CM_ "IMPORT _hyundai_canfd_common.dbc";

BO_ 53 ACCELERATOR: 32 XXX
 SG_ CHECKSUM : 0|16@1+ (1,0) [0|65535] "" XXX
 SG_ COUNTER : 16|8@1+ (1,0) [0|255] "" XXX
 SG_ ACCELERATOR_PEDAL : 40|8@1+ (1,0) [0|255] "" XXX
 SG_ GEAR : 192|3@1+ (1,0) [0|7] "" XXX

BO_ 64 GEAR_ALT: 32 XXX
 SG_ CHECKSUM : 0|16@1+ (1,0) [0|65535] "" XXX
 SG_ COUNTER : 16|8@1+ (1,0) [0|255] "" XXX
 SG_ GEAR : 32|3@1+ (1,0) [0|7] "" XXX
 SG_ GEAR_STEP : 67|4@0+ (1,0) [0|15] "" XXX
 SG_ NEW_SIGNAL_4 : 68|4@1+ (1,0) [0|15] "" XXX
 SG_ NEW_SIGNAL_1 : 75|4@0+ (1,0) [0|15] "" XXX
 SG_ NEW_SIGNAL_3 : 76|4@1+ (1,0) [0|15] "" XXX

BO_ 69 GEAR: 24 XXX
 SG_ CHECKSUM : 0|16@1+ (1,0) [0|65535] "" XXX
 SG_ COUNTER : 16|8@1+ (1,0) [0|255] "" XXX
 SG_ GEAR : 44|3@1+ (1,0) [0|7] "" XXX
 SG_ RIGHT_PADDLE : 57|1@0+ (1,0) [0|1] "" XXX
 SG_ LEFT_PADDLE : 58|1@0+ (1,0) [0|1] "" XXX
 SG_ GEAR_STEP : 146|5@1+ (1,0) [0|31] "" XXX
 SG_ GEAR_STEP1 : 154|5@1+ (1,0) [0|31] "" XXX

BO_ 74 IMU_01_10ms: 32 CGW_CCU
 SG_ IMU_Crc1Val : 0|16@1+ (1,0) [0|0] ""  ECS,ESC,FCU_C,GW_RGW,ICSC,MDPS,RCU,RWS,SFA,VPC_C
 SG_ IMU_AlvCnt1Val : 16|8@1+ (1,0) [0|0] ""  ECS,ESC,FCU_C,GW_RGW,ICSC,MDPS,RCU,RWS,SFA,VPC_C
 SG_ IMU_YawSigSta : 24|4@1+ (1,0) [0|15] ""  CLU,ADAS_PRK,FR_CMR,RR_C_RDR
 SG_ IMU_LatAccelSigSta : 28|4@1+ (1,0) [0|15] ""  CLU,ADAS_PRK,FR_CMR,RR_C_RDR
 SG_ IMU_LongAccelSigSta : 32|4@1+ (1,0) [0|15] ""  CLU,ADAS_PRK,FR_CMR,RR_C_RDR
 SG_ IMU_VerAccelSigSta : 36|4@1+ (1,0) [0|15] "" XXX
 SG_ IMU_McuVoltSta : 40|4@1+ (1,0) [0|15] "" XXX
 SG_ IMU_AcuRstSta : 44|4@1+ (1,0) [0|15] "" XXX
 SG_ IMU_SnsrTyp : 48|8@1+ (1,0) [0|255] "" XXX
 SG_ IMU_RollSigSta : 56|8@1+ (1,0) [0|255] "" XXX
 SG_ IMU_YawRtVal : 64|16@1+ (0.005,-163.84) [-163.84|163.835] "Deg/s"  CLU,ADAS_PRK,FR_CMR,RR_C_RDR
 SG_ IMU_LatAccelVal : 80|16@1+ (0.000127465,-4.17677312) [-4.17677312|4.176645655] "g"  CLU,ADAS_PRK,FR_CMR,RR_C_RDR
 SG_ IMU_LongAccelVal : 96|16@1+ (0.000127465,-4.17677312) [-4.17677312|4.176645655] "g"  CLU,ADAS_PRK,FR_CMR,RR_C_RDR
 SG_ IMU_SnsrTempVal : 112|16@1+ (1,0) [0|65535] "" XXX
 SG_ IMU_SeralNumVal : 128|64@1+ (1,0) [0|1.84467440737096e+19] "" XXX
 SG_ IMU_RollRtVal : 192|16@1+ (0.005,-163.84) [0|0] "º/s" XXX
 SG_ IMU_VerAccelVal : 208|8@1+ (1,0) [0|255] "" XXX

BO_ 96 ESP_STATUS: 32 XXX
 SG_ CHECKSUM : 0|16@1+ (1,0) [0|65535] "" XXX
 SG_ COUNTER : 16|8@1+ (1,0) [0|255] "" XXX
 SG_ TRACTION_AND_STABILITY_CONTROL : 42|3@1+ (1,0) [0|63] "" XXX
 SG_ BRAKE_PRESSURE : 128|11@1+ (1,0) [0|2047] "" XXX
 SG_ BRAKE_PRESSED : 148|1@1+ (1,0) [0|3] "" XXX
 SG_ AUTO_HOLD : 192|2@1+ (1,0) [0|3] "" XXX
 SG_ AVH_I_LAMP : 218|2@1+ (1,0) [0|3] "" XXX
 SG_ AVH_LAMP : 220|3@1+ (1,0) [0|7] "" XXX

BO_ 101 BRAKE: 32 XXX
 SG_ CHECKSUM : 0|16@1+ (1,0) [0|65535] "" XXX
 SG_ COUNTER : 16|8@1+ (1,0) [0|255] "" XXX
 SG_ BRAKE_LIGHT : 29|1@0+ (1,0) [0|1] "" XXX
 SG_ BRAKE_POSITION : 40|16@1- (1,0) [0|65535] "" XXX
 SG_ BRAKE_PRESSED : 57|1@1+ (1,0) [0|3] "" XXX

BO_ 112 GEAR_ALT_2: 32 XXX
 SG_ CHECKSUM : 0|16@1+ (1,0) [0|65535] "" XXX
 SG_ COUNTER : 16|8@1+ (1,0) [0|255] "" XXX
 SG_ GEAR : 60|3@1+ (1,0) [0|7] "" XXX

BO_ 147 CANFD_NAVI_PROFILE_093: 24 XXX
 SG_ PROLONG_VALUE : 64|32@1+ (1,0) [0|4294967295] "" XXX
 SG_ PROLONG_OFFSET : 96|13@1+ (1,0) [0|8191] "m" XXX
 SG_ PROLONG_CYCLIC_COUNTER : 109|2@1+ (1,0) [0|3] "" XXX
 SG_ PROLONG_UPDATE : 111|1@1+ (1,0) [0|1] "" XXX
 SG_ PROLONG_PATH_INDEX : 112|6@1+ (1,0) [0|63] "" XXX
 SG_ PROLONG_PROFILE_TYPE : 118|5@1+ (1,0) [0|31] "" XXX

BO_ 160 WHEEL_SPEEDS: 24 XXX
 SG_ CHECKSUM : 0|16@1+ (1,0) [0|65535] "" XXX
 SG_ COUNTER : 16|8@1+ (1,0) [0|255] "" XXX
 SG_ MOVING_FORWARD : 56|1@0+ (1,0) [0|1] "" XXX
 SG_ MOVING_BACKWARD : 57|1@0+ (1,0) [0|1] "" XXX
 SG_ MOVING_FORWARD2 : 58|1@0+ (1,0) [0|1] "" XXX
 SG_ MOVING_BACKWARD2 : 59|1@0+ (1,0) [0|1] "" XXX
 SG_ WHL_SpdFLVal : 64|14@1+ (0.03125,0) [0|0] "km^h" XXX
 SG_ WHL_SpdFRVal : 80|14@1+ (0.03125,0) [0|0] "km^h" XXX
 SG_ WHL_SpdRLVal : 96|14@1+ (0.03125,0) [0|0] "km^h" XXX
 SG_ WHL_SpdRRVal : 112|14@1+ (0.03125,0) [0|0] "km^h" XXX

BO_ 203 LFA_ALT: 24 CGW_CCU
 SG_ CHECKSUM : 0|16@1+ (1,0) [0|65535] "" FCU_C,GW_RGW,MDPS,SFA
 SG_ COUNTER : 16|8@1+ (1,0) [0|255] "" FCU_C,GW_RGW,MDPS,SFA
 SG_ ADAS_AngleActiveStat : 24|4@1+ (1,0) [0|0] "" GW_RGW,MDPS,SFA
 SG_ ADAS_AngleActiveStat_Lv2 : 28|4@1+ (1,0) [0|0] "" ESC,FCU_C,GW_RGW,MDPS,SFA,VPC_C
 SG_ ADAS_AngleReq : 32|14@1- (0.1,0) [0|511] "Deg" GW_RGW,MDPS,SFA
 SG_ ADAS_AngleTorqueGain : 48|8@1+ (1,0) [0|255] "" GW_RGW,MDPS,SFA
 SG_ FCA_ESA_ActiveStat : 56|2@1+ (1,0) [0|0] "" GW_RGW,MDPS,SFA
 SG_ FCA_ESA_ToqueGain : 64|8@1+ (0.004,0) [0|0] "" GW_RGW,MDPS,SFA

BO_ 229 ESC_02_10ms: 32 CGW
 SG_ ESC_YawSigSta : 24|4@1+ (1,0) [0|15] ""  CLU,ADAS_PRK,FR_CMR,RR_C_RDR
 SG_ ESC_LatAccelSigSta : 28|4@1+ (1,0) [0|15] ""  CLU,ADAS_PRK,FR_CMR,RR_C_RDR
 SG_ ESC_LongAccelSigSta : 32|4@1+ (1,0) [0|15] ""  CLU,ADAS_PRK,FR_CMR,RR_C_RDR
 SG_ ESC_YawRtVal : 64|16@1+ (0.005,-163.84) [-163.84|163.835] "Deg/s"  CLU,ADAS_PRK,FR_CMR,RR_C_RDR
 SG_ ESC_LatAccelVal : 80|16@1+ (0.000127465,-4.17677312) [-4.17677312|4.176645655] "g"  CLU,ADAS_PRK,FR_CMR,RR_C_RDR
 SG_ ESC_LongAccelVal : 96|16@1+ (0.000127465,-4.17677312) [-4.17677312|4.176645655] "g"  CLU,ADAS_PRK,FR_CMR,RR_C_RDR

BO_ 234 MDPS: 24 SFA
 SG_ CHECKSUM : 0|16@1+ (1,0) [0|65535] "" CGW_CCU,ESC,ICSC,RCU,RWA,RWS,VPC_C
 SG_ COUNTER : 16|8@1+ (1,0) [0|255] "" CGW_CCU,ESC,ICSC,RCU,RWA,RWS,VPC_C
 SG_ WarningLamp : 24|3@1+ (1,0) [0|0] "" CGW_CCU,ESC,ICSC,RCU,RWA,RWS
 SG_ Type : 27|3@1+ (1,0) [0|0] "" CGW_CCU,ICSC,RWA
 SG_ EngineIdleRpmReq : 30|2@1+ (1,0) [0|0] "" CGW_CCU,RWA
 SG_ VSM_Stat : 32|2@1+ (1,0) [0|0] "flag" ESC,ICSC,RCU,RWA
 SG_ VSM_DefectiveStat : 34|2@1+ (1,0) [0|0] "" ESC,ICSC,RCU,RWA
 SG_ VSM_SignalStat : 36|2@1+ (1,0) [0|0] "" ESC,RCU,RWA
 SG_ PA_Stat : 38|2@1+ (1,0) [0|0] "" CGW_CCU,ESC,RCU,RWA
 SG_ PA_ModeStat : 40|4@1+ (1,0) [0|0] "" CGW_CCU,RWA
 SG_ PA_CanFailStat : 44|2@1+ (1,0) [0|0] "" CGW_CCU,RWA
 SG_ LKA_Stat : 46|2@1+ (1,0) [0|0] "" CGW_CCU,ICSC,RWA
 SG_ LKA_ToiActiveStat : 48|2@1+ (1,0) [0|16777215] "" CGW_CCU,RWA
 SG_ LKA_ToiUnavailStat : 50|2@1+ (1,0) [0|0] "" CGW_CCU,RWA
 SG_ LKA_ToiFaultStat : 52|2@1+ (1,0) [0|0] "" CGW_CCU,RWA
 SG_ LKA_ToiFailStat : 54|2@1+ (1,0) [0|1] "" CGW_CCU,RWA
 SG_ ResetStat : 59|2@1+ (1,0) [0|0] "" Vector__XXX
 SG_ SteerMode : 61|3@1+ (1,0) [0|0] "" CGW_CCU,RWA
 SG_ OutTorque : 64|12@1+ (0.1,-204.8) [0|65535] "Nm" CGW_CCU,ESC,ICSC,RCU,RWA
 SG_ VSM_ActStat : 76|2@1+ (1,0) [0|0] "" ESC,RCU,RWA
 SG_ ReprogramStat : 78|2@1+ (1,0) [0|0] "" CGW_CCU
 SG_ SteerTorqueSensor : 80|13@1+ (1,-4095) [0|4095] "" CGW_CCU,ESC,ICSC,RCU,RWA,VPC_C
 SG_ PA_SteerAngle : 96|16@1- (0.1,0) [0|255] "Deg" CGW_CCU,RWA
 SG_ LoamStat : 112|2@1+ (1,0) [0|0] "" CGW_CCU,RWA
 SG_ HDPSwVer : 114|5@1+ (1,0) [0|0] "" CGW_CCU,RWA
 SG_ ADAS_ActiveStat : 120|4@1+ (1,0) [0|0] "" CGW_CCU,ESC,RWA,RWS
 SG_ ADAS_AciPlugStat : 124|2@1+ (1,0) [0|0] "" RWA
 SG_ ADAS_AciFault : 126|2@1+ (1,0) [0|0] "" CGW_CCU,ESC,RWA
 SG_ EstSteerAngle : 128|16@1- (0.1,0) [0|65535] "Deg" CGW_CCU,RWA,RWS
 SG_ ADAS_ActiveStat_Lv2 : 144|4@1+ (1,0) [0|0] "" CGW_CCU,RWA
 SG_ ADAS_AciFault_Lv2 : 148|3@1+ (1,0) [0|0] "" CGW_CCU,RWA
 SG_ TPA_Stat : 152|2@1+ (1,0) [0|0] "" RWA,VPC_C
 SG_ TPA_CanFailStat : 154|2@1+ (1,0) [0|0] "" RWA,VPC_C
 SG_ TPA_ModeStat : 156|4@1+ (1,0) [0|0] "" RWA,VPC_C
 SG_ TPA_SteerAngle : 160|16@1- (0.1,0) [0|0] "Deg" RWA,VPC_C

BO_ 256 ACCELERATOR_BRAKE_ALT: 32 XXX
 SG_ CHECKSUM : 0|16@1+ (1,0) [0|65535] "" XXX
 SG_ COUNTER : 16|8@1+ (1,0) [0|255] "" XXX
 SG_ BRAKE_PRESSED : 32|1@1+ (1,0) [0|1] "" XXX
 SG_ ACCELERATOR_PEDAL_PRESSED : 176|1@1+ (1,0) [0|1] "" XXX

BO_ 261 ACCELERATOR_ALT: 32 XXX
 SG_ CHECKSUM : 0|16@1+ (1,0) [0|65535] "" XXX
 SG_ COUNTER : 16|8@1+ (1,0) [0|255] "" XXX
 SG_ ACCELERATOR_PEDAL : 103|10@1+ (0.25,0) [0|1022] "" XXX

BO_ 272 LKAS_ALT: 32 XXX
 SG_ CHECKSUM : 0|16@1+ (1,0) [0|65535] "" XXX
 SG_ COUNTER : 16|8@1+ (1,0) [0|255] "" XXX
 SG_ LKA_OptUsmSta : 24|3@1+ (1,0) [0|7] "" ADAS_DRV
 SG_ LKA_RcgSta : 27|3@1+ (1,0) [0|7] "" ADAS_DRV
 SG_ LKA_LHLnWrnSta : 30|2@1+ (1,0) [0|3] "" ADAS_DRV
 SG_ LKA_RHLnWrnSta : 32|2@1+ (1,0) [0|3] "" ADAS_DRV
 SG_ LKA_HndsoffSnd : 34|2@1+ (1,0) [0|3] "" ADAS_DRV
 SG_ LKA_StrSnd : 36|2@1+ (1,0) [0|3] "" ADAS_DRV
 SG_ LKA_ICON : 38|3@1+ (1,0) [0|7] "" ADAS_DRV
 SG_ StrTqReqVal : 41|11@1+ (1,-1024) [0|4095] "" XXX
 SG_ ActToiSta : 52|2@1+ (1,0) [0|3] "" ADAS_DRV
 SG_ ToiFltSta : 54|2@1+ (1,0) [0|3] "" ADAS_DRV
 SG_ LFA_BUTTON : 56|1@1+ (1,0) [0|1] "" XXX
 SG_ LKA_SysWrn : 60|4@1+ (1,0) [0|15] "" ADAS_DRV
 SG_ Damping_Gain : 64|8@1+ (1,0) [0|255] "" CGW
 SG_ ADAS_AngleActiveStat_Lv2 : 77|2@0+ (1,0) [0|3] "" XXX
 SG_ LKA_UsmMod : 80|2@1+ (1,0) [0|3] "" ADAS_DRV
 SG_ ADAS_AngleReq : 82|14@1- (0.1,0) [0|511] "deg" GW_RGW,MDPS,SFA
 SG_ ADAS_AngleTorqueGain : 96|8@1+ (1,0) [0|255] "" GW_RGW,MDPS,SFA
 SG_ FCA_ESA_CtrlSta : 107|1@0+ (1,0) [0|1] "" XXX

BO_ 282 ADAS_CAM: 16 CAMERA
 SG_ CHECKSUM : 0|16@1+ (1,0) [0|65535] "" Dummy,IBU_HS,vBDM
 SG_ COUNTER : 16|8@1+ (1,0) [0|255] "" CLU,IBU_HS,vBDM
 SG_ HBA_SysOptSta : 24|2@1+ (1,0) [0|3] "" CLU,IBU_HS,vBDM
 SG_ HBA_SysSta : 26|3@1+ (1,0) [0|7] "" CLU,IBU_HS,vBDM
 SG_ HBA_IndLmpReq : 29|2@1+ (1,0) [0|3] "" CLU,vBDM
 SG_ iHBAref_VehLeftSta : 31|2@1+ (1,0) [0|3] "" IBU_HS,ICU,vBDM
 SG_ iHBAref_VehCtrSta : 33|2@1+ (1,0) [0|3] "" IBU_HS,ICU,vBDM
 SG_ iHBAref_VehRightSta : 35|2@1+ (1,0) [0|3] "" IBU_HS,ICU,vBDM
 SG_ iHBAref_ILLAmbtSta : 37|2@1+ (1,0) [0|3] "" IBU_HS,ICU,vBDM
 SG_ FCA_Equip_MFC : 39|3@1+ (1,0) [0|0] "" ADAS_DRV,RR_C_RDR,vBDM
 SG_ HBA_OptUsmSta : 42|2@1+ (1,0) [0|3] "" CLU,H_U_MM
 SG_ FCAref_FusSta : 45|3@1+ (1,0) [0|0] "" vBDM
 SG_ DAW_LVDA_PUDis : 48|2@1+ (1,0) [0|0] "" CLU,vBDM
 SG_ DAW_LVDA_OptUsmSta : 50|2@1+ (1,0) [0|3] "" CLU,H_U_MM,vBDM
 SG_ DAW_OptUsmSta : 52|3@1+ (1,0) [0|0] "" CLU,H_U_MM
 SG_ DAW_SysSta : 55|4@1+ (1,0) [0|0] "" CLU
 SG_ DAW_WrnMsgSta : 59|3@1+ (1,0) [0|0] "" CLU
 SG_ DAW_TimeRstReq : 62|2@1+ (1,0) [0|0] "" CLU
 SG_ DAW_SnstvtyModRetVal : 64|3@1+ (1,0) [0|0] "" CLU,H_U_MMz
 SG_ SCCEquipStat : 85|2@1+ (1,0) [0|3] "" CGW
 SG_ DASMapMsg : 96|16@1+ (1,0) [0|65535] "" CGW
 SG_ SwVer1 : 112|4@1+ (1,0) [0|15] "" CGW
 SG_ SwVer2 : 120|8@1+ (1,0) [0|255] "" CGW

BO_ 293 STEERING_SENSORS: 16 XXX
 SG_ CHECKSUM : 0|16@1+ (1,0) [0|65535] "" XXX
 SG_ COUNTER : 16|8@1+ (1,0) [0|255] "" XXX
 SG_ STEERING_ANGLE : 24|16@1- (0.1,0) [0|511] "deg" XXX
 SG_ STEERING_RATE : 40|8@1+ (4,0) [0|1016] "deg/s" XXX

BO_ 298 LFA: 16 ADRV
 SG_ CHECKSUM : 0|16@1+ (1,0) [0|65535] "" CLU,CGW
 SG_ COUNTER : 16|8@1+ (1,0) [0|255] "" CLU,CGW
 SG_ LKA_OptUsmSta : 24|3@1+ (1,0) [0|7] "" CLU,CGW
 SG_ LKA_RcgSta : 27|3@1+ (1,0) [0|7] "" CLU,CGW
 SG_ LKA_LHLnWrnSta : 30|2@1+ (1,0) [0|3] "" CLU,CGW
 SG_ LKA_RHLnWrnSta : 32|2@1+ (1,0) [0|3] "" CLU,CGW
 SG_ LKA_HndsoffSnd : 34|2@1+ (1,0) [0|3] "" CLU,CGW
 SG_ LKA_StrSnd : 36|2@1+ (1,0) [0|3] "" CLU,CGW
 SG_ LKA_ICON : 38|3@1+ (1,0) [0|7] "" CLU,RR_C_RDR,CGW
 SG_ StrTqReqVal : 41|11@1+ (1,-1024) [0|4095] "" XXX
 SG_ ActToiSta : 52|2@1+ (1,0) [0|3] "" CLU,CGW
 SG_ ToiFltSta : 54|2@1+ (1,0) [0|3] "" CGW
 SG_ LFA_BUTTON : 56|1@0+ (1,0) [0|255] "" XXX
 SG_ BCA_Rear_WrnSta : 57|3@1+ (1,0) [0|255] "" ADRV
 SG_ LKA_SysWrn : 60|4@1+ (1,0) [0|15] "" CLU,CGW
 SG_ FCA_LO_WrnSta : 64|1@1+ (1,0) [0|1] "" ADRV
 SG_ FCA_LS_WrnSta : 68|1@1+ (1,0) [0|1] "" ADRV
 SG_ LKA_OnOffEquip2Sta : 72|2@1+ (1,0) [0|255] "" ADRV
 SG_ LKA_UsmMod : 80|2@1+ (1,0) [0|3] "" CLU,CGW
 SG_ Info_PedtrnDst : 84|3@0+ (1,0) [0|7] "" ADAS_DRV
 SG_ ELK_SysFlrSta : 85|5@1+ (1,0) [0|31] "" ADRV
 SG_ ELK_SymbDisp : 90|3@1+ (1,0) [0|7] "" ADRV
 SG_ FCA_ESA_WrnSta : 93|1@1+ (1,0) [0|7] "" ADRV
 SG_ FCA_ESA_CtrlSta : 101|1@1+ (1,0) [0|7] "" ADRV
 SG_ Damping_Gain : 104|8@1+ (1,0) [0|255] "" CGW

BO_ 304 GEAR_SHIFTER: 16 XXX
 SG_ CHECKSUM : 0|16@1+ (1,0) [0|65535] "" XXX
 SG_ COUNTER : 16|8@1+ (1,0) [0|255] "" XXX
 SG_ PARK_BUTTON : 32|2@1+ (1,0) [0|3] "" XXX
 SG_ KNOB_POSITION : 40|3@1+ (1,0) [0|3] "" XXX
 SG_ GEAR : 64|3@1+ (1,0) [0|7] "" XXX

BO_ 352 ADRV_0x160: 16 ADRV
 SG_ CHECKSUM : 0|16@1+ (1,0) [0|65535] "" XXX
 SG_ COUNTER : 16|8@1+ (1,0) [0|255] "" XXX
 SG_ AEB_SETTING : 24|2@1+ (1,0) [0|255] "" XXX
 SG_ NEW_SIGNAL_1 : 30|1@0+ (1,0) [0|1] "" XXX
 SG_ NEW_SIGNAL_4 : 31|1@0+ (1,0) [0|1] "" XXX
 SG_ NEW_SIGNAL_5 : 39|8@0+ (1,0) [0|255] "" XXX
 SG_ NEW_SIGNAL_6 : 47|8@0+ (1,0) [0|255] "" XXX
 SG_ NEW_SIGNAL_2 : 55|8@0+ (1,0) [0|255] "" XXX
 SG_ SET_ME_2 : 56|8@1+ (1,0) [0|1] "" XXX
 SG_ SET_ME_FF : 64|8@1+ (1,0) [0|255] "" XXX
 SG_ SET_ME_FC : 72|8@1+ (1,0) [0|255] "" XXX
 SG_ SET_ME_9 : 80|8@1+ (1,0) [0|255] "" XXX
 SG_ NEW_SIGNAL_3 : 95|8@0+ (1,0) [0|255] "" XXX
 SG_ NEW_SIGNAL_7 : 102|1@0+ (1,0) [0|1] "" XXX

BO_ 353 CCNC_0x161: 32 CCNC
 SG_ CHECKSUM : 0|16@1+ (1,0) [0|65535] "" XXX
 SG_ COUNTER : 16|8@1+ (1,0) [0|255] "" XXX
 SG_ FCA_ICON : 24|3@1+ (1,0) [0|7] "" XXX
 SG_ FCA_ALT_ICON : 27|3@1+ (1,0) [0|7] "" XXX
 SG_ LKA_ICON : 30|3@1+ (1,0) [0|3] "" XXX
 SG_ HBA_ICON : 33|3@1+ (1,0) [0|7] "" XXX
 SG_ FCA_IMAGE : 42|3@1+ (1,0) [0|7] "" XXX
 SG_ BCA_LEFT : 51|3@1+ (1,0) [0|7] "" XXX
 SG_ BCA_RIGHT : 54|3@1+ (1,0) [0|7] "" XXX
 SG_ LCA_LEFT_ARROW : 57|3@1+ (1,0) [0|7] "" XXX
 SG_ LCA_RIGHT_ARROW : 60|3@1+ (1,0) [0|7] "" XXX
 SG_ CENTERLINE : 64|2@1+ (1,0) [0|3] "" XXX
 SG_ TARGET : 66|3@1+ (1,0) [0|7] "" XXX
 SG_ TARGET_DISTANCE : 69|11@1+ (0.1,0) [0|204.7] "m" XXX
 SG_ LANELINE_LEFT : 80|4@1+ (1,0) [0|15] "" XXX
 SG_ LANELINE_LEFT_POSITION : 84|6@1+ (1,0) [0|15] "" XXX
 SG_ LANELINE_RIGHT : 90|4@1+ (1,0) [0|15] "" XXX
 SG_ LANELINE_RIGHT_POSITION : 94|6@1+ (1,0) [0|15] "" XXX
 SG_ LANELINE_CURVATURE : 100|4@1+ (1,0) [0|15] "" XXX
 SG_ LANELINE_CURVATURE_DIRECTION : 104|1@0+ (1,0) [0|1] "" XXX
 SG_ LANE_HIGHLIGHT : 105|4@1+ (1,0) [0|15] "" XXX
 SG_ LANE_HIGHLIGHT_DISTANCE : 109|11@1+ (0.1,0) [0|204.7] "m" XXX
 SG_ LANE_LEFT : 120|3@1+ (1,0) [0|7] "" XXX
 SG_ LANE_RIGHT : 123|3@1+ (1,0) [0|7] "" XXX
 SG_ LANE_ZOOM : 126|2@1+ (1,0) [0|3] "" XXX
 SG_ ALERTS_1 : 128|6@1+ (1,0) [0|63] "" XXX
 SG_ ALERTS_2 : 134|5@1+ (1,0) [0|31] "" XXX
 SG_ ALERTS_3 : 139|5@1+ (1,0) [0|31] "" XXX
 SG_ ALERTS_4 : 144|8@1+ (1,0) [0|255] "" XXX
 SG_ ALERTS_5 : 152|5@1+ (1,0) [0|31] "" XXX
 SG_ MUTE : 157|3@1+ (1,0) [0|7] "" XXX
 SG_ SOUNDS_1 : 160|4@1+ (1,0) [0|3] "" XXX
 SG_ SOUNDS_2 : 164|4@1+ (1,0) [0|3] "" XXX
 SG_ SOUNDS_3 : 168|4@1+ (1,0) [0|15] "" XXX
 SG_ SOUNDS_4 : 172|3@1+ (1,0) [0|7] "" XXX
 SG_ SETSPEED_HUD : 181|3@1+ (1,0) [0|7] "" XXX
 SG_ DISTANCE_LEAD : 184|5@1+ (1,0) [0|31] "" XXX
 SG_ DISTANCE_CAR : 189|3@1+ (1,0) [0|7] "" XXX
 SG_ DISTANCE_SPACING : 192|4@1+ (1,0) [0|15] "" XXX
 SG_ DISTANCE : 196|4@1+ (1,0) [0|7] "" XXX
 SG_ vSetDis : 200|8@1+ (1,0) [0|255] "" XXX
 SG_ SETSPEED : 208|4@1+ (1,0) [0|7] "" XXX
 SG_ HDA_ICON : 212|3@1+ (1,0) [0|7] "" XXX
 SG_ SLA_ICON : 216|4@1+ (1,0) [0|15] "" XXX
 SG_ NAV_ICON : 220|3@1+ (1,0) [0|7] "" XXX
 SG_ LFA_ICON : 224|3@1+ (1,0) [0|7] "" XXX
 SG_ LCA_LEFT_ICON : 228|3@1+ (1,0) [0|7] "" XXX
 SG_ LCA_RIGHT_ICON : 232|3@1+ (1,0) [0|7] "" XXX
 SG_ BACKGROUND : 236|4@1+ (1,0) [0|15] "" XXX
 SG_ DAW_ICON : 240|3@1+ (1,0) [0|7] "" XXX
 SG_ CAR_CIRCLE : 243|3@1+ (1,0) [0|7] "" XXX

BO_ 354 CCNC_0x162: 32 CCNC
 SG_ CHECKSUM : 0|16@1+ (1,0) [0|65535] "" XXX
 SG_ COUNTER : 16|8@1+ (1,0) [0|255] "" XXX
 SG_ COUNTRY : 24|4@1+ (1,0) [0|15] "" XXX
 SG_ SPEEDLIMIT_FLASH : 28|4@1+ (1,0) [0|15] "" XXX
 SG_ SPEEDLIMIT : 32|8@1+ (1,0) [0|255] "" XXX
 SG_ ROAD_SIGNS : 40|8@1+ (1,0) [0|255] "" XXX
 SG_ SPEEDLIMIT_WEATHER : 48|4@1+ (1,0) [0|15] "" XXX
 SG_ VIBRATE : 52|1@0+ (1,0) [0|1] "" XXX
 SG_ FF_DETECT : 64|5@1+ (1,0) [0|31] "" XXX
 SG_ FF_DETECT_DISTANCE : 69|11@1+ (0.1,0) [0|204.7] "m" XXX
 SG_ FF_DETECT_LATERAL : 80|7@1+ (0.1,0) [0|127] "m" XXX
 SG_ FF_DETECT_ALT : 88|5@1+ (1,0) [0|31] "" XXX
 SG_ FF_DETECT_DISTANCE_ALT : 93|11@1+ (0.1,0) [0|204.7] "m" XXX
 SG_ FF_DETECT_LATERAL_ALT : 104|7@1+ (0.1,0) [0|127] "m" XXX
 SG_ LF_DETECT : 112|5@1+ (1,0) [0|31] "" XXX
 SG_ LF_DETECT_DISTANCE : 117|11@1+ (0.1,0) [0|204.7] "m" XXX
 SG_ LF_DETECT_LATERAL : 128|7@1+ (0.1,0) [0|127] "m" XXX
 SG_ RF_DETECT : 136|5@1+ (1,0) [0|31] "" XXX
 SG_ RF_DETECT_DISTANCE : 141|11@1+ (0.1,0) [0|204.7] "m" XXX
 SG_ RF_DETECT_LATERAL : 152|7@1+ (0.1,0) [0|127] "m" XXX
 SG_ LR_DETECT : 163|5@1+ (1,0) [0|31] "" XXX
 SG_ LR_DETECT_DISTANCE : 175|8@0+ (0.1,0) [0|255] "m" XXX
 SG_ LR_DETECT_LATERAL : 176|7@1+ (0.1,0) [0|127] "m" XXX
 SG_ RR_DETECT : 192|5@1+ (1,0) [0|31] "" XXX
 SG_ RR_DETECT_DISTANCE : 197|8@1+ (0.1,0) [0|255] "m" XXX
 SG_ RR_DETECT_LATERAL : 205|7@1+ (0.1,0) [0|127] "m" XXX
 SG_ FAULT_FSS : 213|3@1+ (1,0) [0|7] "" XXX
 SG_ FAULT_FCA : 216|3@1+ (1,0) [0|7] "" XXX
 SG_ FAULT_LSS : 219|3@1+ (1,0) [0|7] "" XXX
 SG_ FAULT_SLA : 222|3@1+ (1,0) [0|7] "" XXX
 SG_ FAULT_DAW : 225|3@1+ (1,0) [0|7] "" XXX
 SG_ FAULT_HBA : 228|3@1+ (1,0) [0|7] "" XXX
 SG_ FAULT_SCC : 231|3@1+ (1,0) [0|7] "" XXX
 SG_ FAULT_LFA : 234|3@1+ (1,0) [0|7] "" XXX
 SG_ FAULT_HDA : 237|3@1+ (1,0) [0|7] "" XXX
 SG_ FAULT_LCA : 240|3@1+ (1,0) [0|7] "" XXX
 SG_ FAULT_HDP : 243|3@1+ (1,0) [0|7] "" XXX
 SG_ FAULT_DAS : 246|3@1+ (1,0) [0|7] "" XXX
 SG_ FAULT_ESS : 249|3@1+ (1,0) [0|7] "" XXX

BO_ 357 SPAS1: 24 APRK
 SG_ CHECKSUM : 0|16@1+ (1,0) [0|65535] "" XXX
 SG_ COUNTER : 16|8@1+ (1,0) [0|0] "" XXX
 SG_ NEW_SIGNAL_2 : 90|3@1+ (1,0) [0|0] "" XXX
 SG_ NEW_SIGNAL_1 : 96|16@1- (0.1,0) [0|0] "" XXX

BO_ 362 SPAS2: 32 APRK
 SG_ CHECKSUM : 0|16@1+ (1,0) [0|65535] "" XXX
 SG_ COUNTER : 16|8@1+ (1,0) [0|0] "" XXX
 SG_ BLINKER_CONTROL : 133|3@1+ (1,0) [0|0] "" XXX

BO_ 373 TCS: 24 XXX
 SG_ CHECKSUM : 0|16@1+ (1,0) [0|65535] "" XXX
 SG_ COUNTER : 16|8@1+ (1,0) [0|255] "" XXX
 SG_ NEW_SIGNAL_4 : 24|7@1+ (1,0) [0|127] "" XXX
 SG_ NEW_SIGNAL_9 : 31|1@0+ (1,0) [0|1] "" XXX
 SG_ aBasis : 32|11@1+ (0.01,-10.23) [0|7] "m/s^2" XXX
 SG_ NEW_SIGNAL_1 : 47|5@0+ (1,0) [0|31] "" XXX
 SG_ ACCEL_REF_ACC : 48|11@1- (1,0) [0|1023] "" XXX
 SG_ NEW_SIGNAL_2 : 63|5@0+ (1,0) [0|31] "" XXX
 SG_ SCC_OptTyp : 64|2@1+ (1,0) [0|0] "" AWD,EMS,FR_CMR,HCU,H_U_MM,TCU,VCU,vBDM
 SG_ ACCEnable : 67|2@0+ (1,0) [0|3] "" XXX
 SG_ ACC_REQ : 68|1@0+ (1,0) [0|1] "" XXX
 SG_ NEW_SIGNAL_3 : 69|1@0+ (1,0) [0|1] "" XXX
 SG_ SCC_ReqLimSta : 70|2@1+ (1,0) [0|0] "" ADAS_DRV,AWD,Dummy,EMS,FR_CMR,H_U_MM,TCU,vBDM
 SG_ ESC_StdStillVal : 72|2@1+ (1,0) [0|3] "" ADAS_DRV,AWD,Dummy,EMS,FR_CMR,H_U_MM,TCU,vBDM
 SG_ BrakeLight : 74|2@1+ (1,0) [0|3] "" XXX
 SG_ ESC_DclEnblReq : 76|2@1+ (1,0) [0|3] "" AWD,Dummy,EMS,FR_CMR,H_U_MM,TCU,vBDM
 SG_ NEW_SIGNAL_5 : 79|2@0+ (1,0) [0|3] "" XXX
 SG_ NEW_SIGNAL_21 : 80|1@0+ (1,0) [0|1] "" XXX
 SG_ DriverBraking : 81|1@0+ (1,0) [0|1] "" XXX
 SG_ NEW_SIGNAL_20 : 82|1@0+ (1,0) [0|1] "" XXX
 SG_ NEW_SIGNAL_11 : 83|1@0+ (1,0) [0|1] "" XXX
 SG_ DriverBrakingLowSens : 84|1@1+ (1,0) [0|1] "" XXX
 SG_ NEW_SIGNAL_10 : 85|1@0+ (1,0) [0|1] "" XXX
 SG_ ESC_PrkBrkActvSta : 86|2@1+ (1,0) [0|3] "" ADAS_DRV,AWD,Dummy,EMS,FR_CMR,H_U_MM,RR_C_RDR,TCU,vBDM
 SG_ NEW_SIGNAL_12 : 95|8@0+ (1,0) [0|255] "" XXX
 SG_ FCA_EquipSta : 96|2@1+ (1,0) [0|3] "" ADAS_DRV,FR_CMR,H_U_MM,vBDM
 SG_ FCA_AvlblSta : 98|2@1+ (1,0) [0|3] "" ADAS_DRV,AFCU_DRV,CLU,Dummy,FR_CMR,H_U_MM,vBDM
 SG_ NEW_SIGNAL_13 : 103|4@0+ (1,0) [0|15] "" XXX
 SG_ NEW_SIGNAL_14 : 111|8@0+ (1,0) [0|255] "" XXX
 SG_ NEW_SIGNAL_15 : 119|8@0+ (1,0) [0|255] "" XXX
 SG_ NEW_SIGNAL_16 : 127|8@0+ (1,0) [0|255] "" XXX
 SG_ NEW_SIGNAL_6 : 128|4@1+ (1,0) [0|15] "" XXX
 SG_ NEW_SIGNAL_17 : 133|2@0+ (1,0) [0|3] "" XXX
 SG_ NEW_SIGNAL_7 : 135|2@0+ (1,0) [0|3] "" XXX
 SG_ PROBABLY_EQUIP : 136|2@1+ (1,0) [0|3] "" XXX
 SG_ NEW_SIGNAL_18 : 143|6@0+ (1,0) [0|63] "" XXX
 SG_ NEW_SIGNAL_19 : 151|8@0+ (1,0) [0|255] "" XXX
 SG_ NEW_SIGNAL_8 : 183|16@0+ (1,0) [0|65535] "" XXX

BO_ 416 SCC_CONTROL: 32 ADRV
 SG_ CHECKSUM : 0|16@1+ (1,0) [0|65535] "" XXX
 SG_ COUNTER : 16|8@1+ (1,0) [0|255] "" XXX
 SG_ ObjectDistance : 24|11@1+ (0.1,0) [0|204.7] "m" CLU,CGW
 SG_ ObjectRelativeSpeed : 35|12@1+ (0.1,-170) [-16.4|34.7] "m/s" CGW
 SG_ ObjectLateralPosition : 47|9@1+ (0.1,-20) [-20|31.1] "m" CLU,CGW
 SG_ SET_ME_TMP_64 : 56|8@1+ (1,0) [0|63] "" XXX
 SG_ SysFailStat : 64|2@1+ (1,0) [0|3] "" CLU,CGW
 SG_ MainMode_ACC : 66|2@1+ (1,0) [0|3] "" CLU,CGW
 SG_ ACCMode : 68|3@1+ (1,0) [0|7] "" CLU,CGW
 SG_ TakeoverReq : 72|2@1+ (1,0) [0|3] "" CLU,CGW
 SG_ InfoDisplay : 74|3@1+ (1,0) [0|7] "" CLU,CGW
 SG_ AlertDisplay : 77|2@1+ (1,0) [0|3] "" CLU,CGW
 SG_ ObjectDistanceLevel : 80|8@1+ (1,0) [0|255] "" CLU,CGW
 SG_ DistanceGapSet : 88|4@1+ (1,0) [0|15] "" CLU,CGW
 SG_ NSCC_AutoSetStat : 94|2@1+ (1,0) [0|3] "" CLU,CGW
 SG_ VSetDis : 96|8@1+ (1,0) [0|255] "km/h or MPH" CLU,CGW
 SG_ NSCC_OperationStat : 104|2@1+ (1,0) [0|3] "" CLU,CGW
 SG_ NSCC_MainStat : 106|2@1+ (1,0) [0|3] "" CLU,CGW
 SG_ ObjectStat : 108|3@1+ (1,0) [0|7] "" CLU,CGW
 SG_ SensitiveMode : 112|3@1+ (1,0) [0|7] "" CLU,CGW
 SG_ NSCC_AutoSetSpeedStat : 115|2@1+ (1,0) [0|3] "" CLU,CGW
 SG_ NSCC_InfoDisplay : 117|3@1+ (1,0) [0|7] "" CLU,CGW
 SG_ AccelRequest : 128|11@1+ (0.01,-10.23) [-10.23|10.24] "m/s^2" CGW
 SG_ AccelRequestRaw : 140|11@1+ (0.01,-10.23) [-10.23|10.24] "m/s^2" CGW
 SG_ JerkUpperLimit : 152|7@1+ (0.1,0) [0|12.7] "m/s^3" CGW
 SG_ JerkLowerLimit : 160|7@1+ (0.1,0) [0|12.7] "m/s^3" CGW
 SG_ AccelLimitBandUpper : 168|6@1+ (0.02,0) [0|1.26] "m/s^2" CGW
 SG_ AccelLimitBandLower : 176|6@1+ (0.02,0) [0|1.26] "m/s^2" CGW
 SG_ StopReq : 184|2@1+ (1,0) [0|3] "" CGW
 SG_ EngineStopReq : 188|2@1+ (1,0) [0|3] "" CGW
 SG_ TargetDistance : 192|11@1+ (0.1,0) [0|204.7] "m" CLU,CGW

BO_ 426 CRUISE_BUTTONS_ALT: 16 XXX
 SG_ CHECKSUM : 0|16@1+ (1,0) [0|65535] "" XXX
 SG_ COUNTER : 16|8@1+ (1,0) [0|255] "" XXX
 SG_ NEW_SIGNAL_1 : 24|4@1+ (1,0) [0|15] "" XXX
 SG_ SET_ME_1 : 28|2@1+ (1,0) [0|3] "" XXX
 SG_ DISTANCE_UNIT : 30|1@1+ (1,0) [0|1] "" XXX
 SG_ NEW_SIGNAL_2 : 31|3@1+ (1,0) [0|7] "" XXX
 SG_ ADAPTIVE_CRUISE_MAIN_BTN : 34|1@1+ (1,0) [0|1] "" XXX
 SG_ NEW_SIGNAL_3 : 35|1@1+ (1,0) [0|1] "" XXX
 SG_ CRUISE_BUTTONS : 36|3@1+ (1,0) [0|4] "" XXX
 SG_ LDA_BTN : 39|1@1+ (1,0) [0|1] "" XXX
 SG_ NEW_SIGNAL_4 : 40|1@1+ (1,0) [0|1] "" XXX
 SG_ NORMAL_CRUISE_MAIN_BTN : 41|1@1+ (1,0) [0|1] "" XXX
 SG_ NEW_SIGNAL_5 : 42|2@1+ (1,0) [0|3] "" XXX
 SG_ SET_ME_2 : 44|3@1+ (1,0) [0|7] "" XXX
 SG_ NEW_SIGNAL_6 : 47|1@1+ (1,0) [0|1] "" XXX
 SG_ CLUSTER_SPEED_MPH : 48|8@1+ (0.5,0) [0|255] "mph" XXX
 SG_ BYTE7 : 56|8@1+ (1,0) [0|255] "" XXX
 SG_ CLUSTER_SPEED_KPH : 64|8@1+ (1,0) [0|255] "kph" XXX
 SG_ BYTE9 : 72|8@1+ (1,0) [0|255] "" XXX
 SG_ BYTE10 : 80|8@1+ (1,0) [0|255] "" XXX
 SG_ BYTE11 : 88|8@1+ (1,0) [0|255] "" XXX
 SG_ BYTE12 : 96|8@1+ (1,0) [0|255] "" XXX
 SG_ BYTE13 : 104|8@1+ (1,0) [0|255] "" XXX
 SG_ BYTE14 : 112|8@1+ (1,0) [0|255] "" XXX
 SG_ BYTE15 : 120|8@1+ (1,0) [0|255] "" XXX

BO_ 437 CCNC_0x1b5: 32 CAMERA
 SG_ CHECKSUM : 0|16@1+ (1,0) [0|65535] "" RR_C_RDR,CGW
 SG_ COUNTER : 16|8@1+ (1,0) [0|255] "" RR_C_RDR,CGW
 SG_ LeftLnQualStat : 24|3@1+ (1,0) [0|7] "" RR_C_RDR,CGW
 SG_ LeftLnDptStat : 27|2@1+ (1,0) [0|3] "" RR_C_RDR,CGW
 SG_ LeftLnPosition : 29|14@1- (0.0039625,0) [-32.4608|32.4568375] "m" RR_C_RDR,CGW
 SG_ LeftLnHeadingAngle : 43|10@1- (0.000976563,0) [-0.500000256|0.499023693] "rad" RR_C_RDR,CGW
 SG_ LeftLnCurvature : 64|16@1- (1e-06,0) [-0.032768|0.032767] "1/m" CGW
 SG_ LeftLnCurvatureRate : 80|16@1- (4e-09,0) [-0.000131072|0.000131068] "1/m2" CGW
 SG_ RightLnQualStat : 96|3@1+ (1,0) [0|7] "" RR_C_RDR,CGW
 SG_ RightLnDptStat : 99|2@1+ (1,0) [0|3] "" RR_C_RDR,CGW
 SG_ RightLnPosition : 101|14@1- (0.0039625,0) [-32.4608|32.4568375] "m" RR_C_RDR,CGW
 SG_ RightLnHeadingAngle : 115|10@1- (0.000976563,0) [-0.500000256|0.499023693] "rad" RR_C_RDR,CGW
 SG_ RightLnCurvature : 128|16@1- (1e-06,0) [-0.032768|0.032767] "1/m" CGW
 SG_ RightLnCurvatureRate : 144|16@1- (4e-09,0) [-0.000131072|0.000131068] "1/m2" CGW
 SG_ ID_CIPV : 192|8@1+ (1,0) [0|255] "" XXX
 SG_ Relative_Velocity : 200|12@1+ (0.05,-100) [-100|104.75] "m/s" XXX
 SG_ Longitudinal_Distance : 212|12@1+ (0.05,0) [0|204.75] "m" XXX

BO_ 442 BLINDSPOTS_REAR_CORNERS: 24 XXX
 SG_ CHECKSUM : 0|16@1+ (1,0) [0|65535] "" XXX
 SG_ COUNTER : 16|8@1+ (1,0) [0|255] "" XXX
 SG_ BCW_Sta : 24|1@0+ (1,0) [0|1] "" XXX
 SG_ BCW_OnOffEquipSta : 28|2@1+ (1,0) [0|3] "" XXX
 SG_ BCW_LeftIndSta : 31|2@0+ (1,0) [0|3] "" XXX
 SG_ BCW_RightIndSta : 32|2@1+ (1,0) [0|3] "" XXX
 SG_ BCW_LeftSndWrngSta : 34|2@1+ (1,0) [0|3] "" XXX
 SG_ BCW_RightSndWrngSta : 36|10@1+ (1,0) [0|1023] "" XXX
 SG_ BCW_SnstvtyModRetVal : 56|3@1+ (1,0) [0|7] "" XXX
 SG_ BCW_IndSta : 59|3@1+ (1,0) [0|7] "" XXX
 SG_ BCA_OnOffEquip2Sta : 62|2@1+ (1,0) [0|3] "" XXX
 SG_ BCA_Sta : 64|1@0+ (1,0) [0|1] "" XXX
 SG_ BCA_OnOffEquipSta : 68|1@0+ (1,0) [0|1] "" XXX
 SG_ BCA_DRV_WarnSta : 76|4@1+ (1,0) [0|15] "" XXX
 SG_ BCA_Plus_Deccel_Req : 80|4@1+ (1,0) [0|15] "" XXX
 SG_ BCA_Plus_BrkCmdSta : 84|2@1+ (1,0) [0|3] "" XXX
 SG_ BCA_Plus_LtWrngSta : 86|2@1+ (1,0) [0|3] "" XXX
 SG_ BCA_Plus_RtWrngSta : 88|5@1+ (1,0) [0|31] "" XXX
 SG_ BCA_Plus_FuncStat : 93|3@1+ (1,0) [0|7] "" XXX
 SG_ BCA_Plus_Sta : 96|1@0+ (1,0) [0|1] "" XXX
 SG_ Brake_Control_RL : 110|2@1+ (1,0) [0|3] "" XXX
 SG_ Brake_Control_RR : 118|2@1+ (1,0) [0|3] "" XXX
 SG_ OSMrrLamp_LeftIndSta : 128|2@1+ (1,0) [0|3] "" XXX
 SG_ OSMrrLamp_RightIndSta : 130|6@1+ (1,0) [0|63] "" XXX

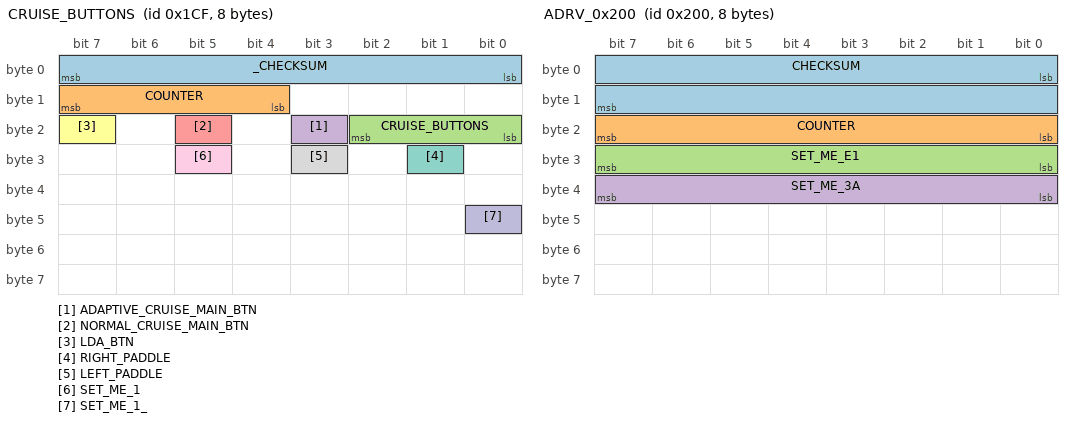
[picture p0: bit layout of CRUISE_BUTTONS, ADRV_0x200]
BO_ 463 CRUISE_BUTTONS: 8 XXX
 SG_ _CHECKSUM : 0|8@1+ (1,0) [0|65535] "" XXX
 SG_ COUNTER : 12|4@1+ (1,0) [0|255] "" XXX
 SG_ CRUISE_BUTTONS : 16|3@1+ (1,0) [0|3] "" XXX
 SG_ ADAPTIVE_CRUISE_MAIN_BTN : 19|1@1+ (1,0) [0|1] "" XXX
 SG_ NORMAL_CRUISE_MAIN_BTN : 21|1@1+ (1,0) [0|1] "" XXX
 SG_ LDA_BTN : 23|1@1+ (1,0) [0|1] "" XXX
 SG_ RIGHT_PADDLE : 25|1@1+ (1,0) [0|1] "" XXX
 SG_ LEFT_PADDLE : 27|1@1+ (1,0) [0|1] "" XXX
 SG_ SET_ME_1 : 29|1@1+ (1,0) [0|1] "" XXX
 SG_ SET_ME_1_ : 40|1@0+ (1,0) [0|1] "" XXX

BO_ 474 ADRV_0x1da: 32 ADRV
 SG_ CHECKSUM : 0|16@1+ (1,0) [0|65535] "" XXX
 SG_ COUNTER : 16|8@1+ (1,0) [0|255] "" XXX
 SG_ SET_ME_22 : 31|8@0+ (1,0) [0|255] "" XXX
 SG_ SET_ME_41 : 47|8@0+ (1,0) [0|255] "" XXX

BO_ 480 LFAHDA_CLUSTER: 16 ADRV
 SG_ CHECKSUM : 0|16@1+ (1,0) [0|65535] "" CGW
 SG_ COUNTER : 16|8@1+ (1,0) [0|255] "" CGW
 SG_ HDA_OptUsmSta : 24|3@1+ (1,0) [0|7] ""  CGW
 SG_ LFA_OptUsmSta : 27|3@1+ (1,0) [0|7] ""  CGW
 SG_ HDA_CntrlModSta : 30|2@1+ (1,0) [0|3] ""  CGW
 SG_ HDA_InfoPUDis : 32|3@1+ (1,0) [0|7] ""  CGW
 SG_ HDA_AutoSetSpdSta : 35|2@1+ (1,0) [0|3] ""  CGW
 SG_ HDA_AutoSetSpdUpdtSta : 37|2@1+ (1,0) [0|3] ""  CGW
 SG_ HDA_AutoSetSpdVal : 39|8@1+ (1,0) [0|255] "km/h"  CGW
 SG_ HDA_LFA_SymSta : 47|2@1+ (1,0) [0|3] ""  CGW
 SG_ HDA_LFA_WrnSnd : 49|2@1+ (1,0) [0|3] ""  Dummy
 SG_ HDA_InfoPUDis1 : 51|3@1+ (1,0) [0|7] ""  CLU,CGW
 SG_ HDA_TDMRMDclReq : 54|2@1+ (1,0) [0|3] ""  Dummy

BO_ 485 BLINDSPOTS_FRONT_CORNER_1: 16 XXX
 SG_ CHECKSUM : 0|16@1+ (1,0) [0|65535] "" XXX
 SG_ COUNTER : 16|8@1+ (1,0) [0|255] "" XXX
 SG_ REVERSING : 24|1@0+ (1,0) [0|1] "" XXX
 SG_ NEW_SIGNAL_5 : 31|2@0+ (1,0) [0|3] "" XXX
 SG_ NEW_SIGNAL_7 : 32|2@1+ (1,0) [0|3] "" XXX
 SG_ NEW_SIGNAL_8 : 47|8@0+ (1,0) [0|255] "" XXX
 SG_ NEW_SIGNAL_9 : 55|8@0+ (1,0) [0|255] "" XXX
 SG_ NEW_SIGNAL_4 : 80|1@0+ (1,0) [0|1] "" XXX
 SG_ NEW_SIGNAL_3 : 88|1@0+ (1,0) [0|1] "" XXX
 SG_ NEW_SIGNAL_2 : 96|1@0+ (1,0) [0|1] "" XXX
 SG_ NEW_SIGNAL_1 : 108|2@0+ (1,0) [0|3] "" XXX

BO_ 490 ADRV_0x1ea: 32 ADRV
 SG_ CHECKSUM : 0|16@1+ (1,0) [0|65535] "" XXX
 SG_ COUNTER : 16|8@1+ (1,0) [0|255] "" XXX
 SG_ NEW_SIGNAL_4 : 25|2@0+ (1,0) [0|3] "" XXX
 SG_ NEW_SIGNAL_3 : 26|1@0+ (1,0) [0|1] "" XXX
 SG_ NEW_SIGNAL_2 : 27|1@0+ (1,0) [0|1] "" XXX
 SG_ NEW_SIGNAL_1 : 28|1@0+ (1,0) [0|1] "" XXX
 SG_ LEFT_BLINK_HOLD : 29|1@0+ (1,0) [0|1] "" XXX
 SG_ RIGHT_BLINK_HOLD : 30|1@0+ (1,0) [0|1] "" XXX
 SG_ NEW_SIGNAL_5 : 31|1@0+ (1,0) [0|1] "" XXX
 SG_ HDA_MODE2 : 32|3@1+ (1,0) [0|3] "" XXX
 SG_ LANE_LEFT : 36|2@0+ (1,0) [0|3] "" XXX
 SG_ NEW_SIGNAL_6 : 39|3@0+ (1,0) [0|7] "" XXX
 SG_ LANE_RIGHT : 41|2@0+ (1,0) [0|3] "" XXX
 SG_ LANE_CHANGING : 45|3@0+ (1,0) [0|1] "" XXX
 SG_ LF_DETECT_DISTANCE : 46|11@1+ (0.1,0) [0|2047] "" XXX
 SG_ LF_DETECT_LATERAL : 70|7@0+ (0.1,0) [0|127] "" XXX
 SG_ LF_DETECT : 74|3@0+ (1,0) [0|7] "" XXX
 SG_ RF_DETECT_DISTANCE : 75|11@1+ (0.1,0) [0|2047] "" XXX
 SG_ RF_DETECT_LATERAL : 94|7@0+ (0.1,0) [0|127] "" XXX
 SG_ RF_DETECT : 98|3@0+ (1,0) [0|7] "" XXX
 SG_ SET_ME_FF : 120|8@1+ (1,0) [0|255] "" XXX
 SG_ LR_DETECT_DISTANCE : 139|8@1+ (0.1,0) [0|511] "m" XXX
 SG_ LR_DETECT_LATERAL : 152|6@1+ (0.1,0) [0|63] "" XXX
 SG_ LR_DETECT : 162|3@0+ (1,0) [0|1] "" XXX
 SG_ RR_DETECT_DISTANCE : 163|8@1+ (0.1,0) [0|511] "m" XXX
 SG_ RR_DETECT_LATERAL : 172|6@1+ (0.1,0) [0|63] "" XXX
 SG_ RR_DETECT : 186|3@0+ (1,0) [0|1] "" XXX
 SG_ AUTOLANECHANGE_MSG : 207|4@0+ (1,0) [0|3] "" XXX
 SG_ LANELINE_CURVATURE : 208|4@1+ (1,0) [0|31] "" XXX
 SG_ LANELINE_CURVATURE_DIRECTION : 212|1@0+ (1,0) [0|1] "" XXX
 SG_ LANELINE_LEFT_POSITION : 239|8@0+ (1,0) [0|255] "" XXX
 SG_ LANELINE_RIGHT_POSITION : 247|8@0+ (1,0) [0|255] "" XXX
 SG_ NEW_SIGNAL_7 : 248|1@0+ (1,0) [0|1] "" XXX

BO_ 506 CLUSTER_SPEED_LIMIT: 32 FR_CMR
 SG_ CHECKSUM : 0|16@1+ (1,0) [0|65535] "" CGW
 SG_ COUNTER : 16|8@1+ (1,0) [0|255] "" CGW
 SG_ ISLW_OptUsmSta : 24|2@1+ (1,0) [0|3] "" CLU,CGW
 SG_ SysSta : 26|2@1+ (1,0) [0|3] "" CLU,CGW
 SG_ NoPassingInfoDis : 28|3@1+ (1,0) [0|7] "" CLU,CGW
 SG_ OvrlpSignDis : 31|2@1+ (1,0) [0|3] "" CLU,CGW
 SG_ CluSpeedLimit : 33|8@1+ (1,0) [0|255] "" CLU,CGW
 SG_ NavSpeedLimit : 41|8@1+ (1,0) [0|255] "" CGW
 SG_ SubCondinfoSta1 : 49|4@1+ (1,0) [0|15] "" CLU,CGW
 SG_ SubCondinfoSta2 : 53|4@1+ (1,0) [0|15] "" CLU,CGW
 SG_ SpdCluSubMainDis : 64|8@1+ (1,0) [0|255] "" CLU
 SG_ SpdCluDisSubCond1 : 72|8@1+ (1,0) [0|255] "" CLU,CGW
 SG_ SpdCluDisSubCond2 : 80|8@1+ (1,0) [0|255] "" CLU,CGW
 SG_ SpdNaviSubMainDis : 88|8@1+ (1,0) [0|255] "" CLU
 SG_ SpdNaviDisSubCond1 : 96|8@1+ (1,0) [0|255] "" CLU,CGW
 SG_ SpdNaviDisSubCond2 : 104|8@1+ (1,0) [0|255] "" CLU,CGW
 SG_ SpdwOffst : 112|8@1+ (1,0) [0|255] "" CLU,CGW
 SG_ SwIgnoreReq : 120|2@1+ (1,0) [0|3] "" CGW
 SG_ SpdChgReq : 122|2@1+ (1,0) [0|3] "" CGW
 SG_ SpdWrn : 124|2@1+ (1,0) [0|3] "" CLU,CGW
 SG_ IcyWrn : 126|2@1+ (1,0) [0|3] "" CLU,CGW
 SG_ SymFlashMod : 128|3@1+ (1,0) [0|7] "" CLU,CGW
 SG_ Popup : 131|3@1+ (1,0) [0|7] "" CLU
 SG_ ISLA_OptUsmSta : 136|3@1+ (1,0) [0|7] "" CLU,CGW
 SG_ OffstUsmSta : 139|3@1+ (1,0) [0|7] "" CLU,CGW
 SG_ AutoUsmSta : 142|2@1+ (1,0) [0|3] "" CLU,CGW
 SG_ Country : 144|4@1+ (1,0) [0|15] "" CLU,CGW
 SG_ ROAD_SIGNS : 149|8@1+ (1,0) [0|255] "" CLU,CGW

BO_ 507 CAM_0x1fb: 32 CAMERA
 SG_ CHECKSUM : 0|16@1+ (1,0) [0|65535] "" XXX
 SG_ COUNTER : 16|8@1+ (1,0) [0|255] "" XXX

BO_ 512 ADRV_0x200: 8 ADRV
 SG_ CHECKSUM : 0|16@1+ (1,0) [0|65535] "" XXX
 SG_ COUNTER : 16|8@1+ (1,0) [0|255] "" XXX
 SG_ SET_ME_E1 : 24|8@1+ (1,0) [0|255] "" XXX
 SG_ SET_ME_3A : 32|8@1+ (1,0) [0|255] "" XXX

BO_ 593 RADAR_0x251: 16 FRONT_RADAR
 SG_ CHECKSUM : 0|16@1+ (1,0) [0|65535] "" XXX
 SG_ COUNTER : 16|8@1+ (1,0) [0|255] "" XXX

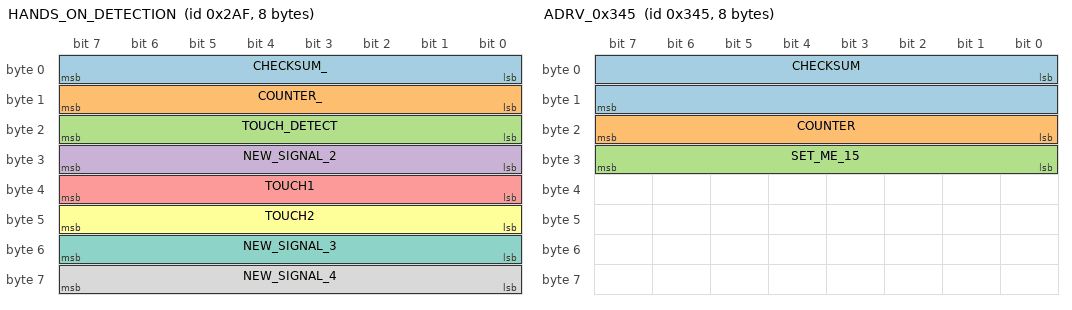
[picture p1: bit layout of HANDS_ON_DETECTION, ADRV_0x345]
BO_ 687 HANDS_ON_DETECTION: 8 HOD
 SG_ CHECKSUM_ : 7|8@0+ (1,0) [0|255] "" XXX
 SG_ COUNTER_ : 8|8@1+ (1,0) [0|255] "" XXX
 SG_ TOUCH_DETECT : 23|8@0+ (1,0) [0|255] "" XXX
 SG_ NEW_SIGNAL_2 : 31|8@0+ (1,0) [0|255] "" XXX
 SG_ TOUCH1 : 39|8@0+ (1,0) [0|255] "" XXX
 SG_ TOUCH2 : 47|8@0+ (1,0) [0|255] "" XXX
 SG_ NEW_SIGNAL_3 : 55|8@0+ (1,0) [0|255] "" XXX
 SG_ NEW_SIGNAL_4 : 63|8@0+ (1,0) [0|255] "" XXX

BO_ 698 IFS: 32 FR_CMR
 SG_ CHECKSUM : 0|16@1+ (1,0) [0|65535] "" Dummy
 SG_ COUNTER : 16|8@1+ (1,0) [0|255] "" Dummy
 SG_ Status : 24|2@1+ (1,0) [0|3] "" CGW
 SG_ VehNumVal : 26|4@1+ (1,0) [0|15] "" CGW
 SG_ ILLAmbtSta : 30|2@1+ (0.1,0) [0|0.3] "" CGW
 SG_ VehLeftAngl1Val : 32|9@1+ (0.1,-25) [-25|26.1] "Deg" CGW
 SG_ VehRightAngl1Val : 41|9@1+ (0.1,-25) [-25|26.1] "Deg" CGW
 SG_ VehLeftAngl2Val : 50|9@1+ (0.1,-25) [-25|26.1] "Deg" CGW
 SG_ VehDst1Val : 59|4@1+ (1,0) [0|15] "" CGW
 SG_ VehRightAngl2Val : 64|9@1+ (0.1,-25) [-25|26.1] "Deg" CGW
 SG_ VehLeftAngl3Val : 73|9@1+ (0.1,-25) [-25|26.1] "Deg" CGW
 SG_ VehRightAngl3Val : 82|9@1+ (0.1,-25) [-25|26.1] "Deg" CGW
 SG_ VehLeftAngl4Val : 91|9@1+ (0.1,-25) [-25|26.1] "Deg" CGW
 SG_ VehRightAngl4Val : 100|9@1+ (0.1,-25) [-25|26.1] "Deg" CGW
 SG_ VehLeftAngl5Val : 109|9@1+ (0.1,-25) [-25|26.1] "Deg" CGW
 SG_ VehRightAngl5Val : 118|9@1+ (0.1,-25) [-25|26.1] "Deg" CGW
 SG_ VehLeftAngl6Val : 128|9@1+ (0.1,-25) [-25|26.1] "Deg" CGW
 SG_ VehRightAngl6Val : 137|9@1+ (0.1,-25) [-25|26.1] "Deg" CGW
 SG_ VehLeftAngl7Val : 146|9@1+ (0.1,-25) [-25|26.1] "Deg" CGW
 SG_ VehRightAngl7Val : 155|9@1+ (0.1,-25) [-25|26.1] "Deg" CGW
 SG_ VehLeftAngl8Val : 164|9@1+ (0.1,-25) [-25|26.1] "Deg" CGW
 SG_ VehRightAngl8Val : 173|9@1+ (0.1,-25) [-25|26.1] "Deg" CGW
 SG_ VehLeftAngl9Val : 182|9@1+ (0.1,-25) [-25|26.1] "Deg" CGW
 SG_ VehRightAngl9Val : 192|9@1+ (0.1,-25) [-25|26.1] "Deg" CGW
 SG_ VehLeftAngl10Val : 201|9@1+ (0.1,-25) [-25|26.1] "Deg" CGW
 SG_ VehRightAngl10Val : 210|9@1+ (0.1,-25) [-25|26.1] "Deg" CGW
 SG_ VehDst2Val : 219|4@1+ (1,0) [0|15] "" CGW
 SG_ VehDst3Val : 223|4@1+ (1,0) [0|15] "" CGW
 SG_ VehDst4Val : 227|4@1+ (1,0) [0|15] "" CGW
 SG_ VehDst5Val : 231|4@1+ (1,0) [0|15] "" CGW
 SG_ VehDst6Val : 235|4@1+ (1,0) [0|15] "" CGW
 SG_ VehDst7Val : 239|4@1+ (1,0) [0|15] "" CGW
 SG_ VehDst8Val : 243|4@1+ (1,0) [0|15] "" CGW
 SG_ VehDst9Val : 247|4@1+ (1,0) [0|15] "" CGW
 SG_ VehDst10Val : 251|4@1+ (1,0) [0|15] "" CGW

BO_ 736 MANUAL_SPEED_LIMIT_ASSIST: 32 XXX
 SG_ CHECKSUM : 0|16@1+ (1,0) [0|65535] "" XXX
 SG_ COUNTER : 16|8@1+ (1,0) [0|255] "" XXX
 SG_ MSLA_STATUS : 26|2@1+ (1,0) [0|3] "" XXX
 SG_ MSLA_ENABLED : 38|1@1+ (1,0) [0|1] "" XXX
 SG_ MAX_SPEED : 55|8@0+ (1,0) [0|255] "" XXX
 SG_ I_PEDAL_STOP : 101|1@0+ (1,0) [0|1] "" XXX
 SG_ REGEN_LEVEL_AUTO : 105|1@0+ (1,0) [0|1] "" XXX
 SG_ REGEN_LEVEL : 110|5@0+ (1,0) [0|63] "" XXX
 SG_ MAX_SPEED_COPY : 144|8@1+ (1,0) [0|255] "" XXX
 SG_ I_PEDAL_MAX : 185|1@0+ (1,0) [0|1] "" XXX

BO_ 837 ADRV_0x345: 8 ADRV
 SG_ CHECKSUM : 0|16@1+ (1,0) [0|65535] "" XXX
 SG_ COUNTER : 16|8@1+ (1,0) [0|255] "" XXX
 SG_ SET_ME_15 : 24|8@1+ (1,0) [0|255] "" XXX

BO_ 866 CAM_0x362: 32 CAMERA
 SG_ CHECKSUM : 0|16@1+ (1,0) [0|65535] "" XXX
 SG_ COUNTER : 16|8@1+ (1,0) [0|255] "" XXX
 SG_ LEFT_LANE_PROB : 31|8@0+ (1,0) [0|255] "" XXX
 SG_ RIGHT_LANE_PROB : 39|8@0+ (1,0) [0|255] "" XXX
 SG_ LEFT_LANE_TYPE : 43|4@0+ (1,0) [0|15] "" XXX
 SG_ RIGHT_LANE_TYPE : 47|4@0+ (1,0) [0|15] "" XXX
 SG_ LEFT_LANE_COLOR : 48|4@1+ (1,0) [0|15] "" XXX
 SG_ RIGHT_LANE_COLOR : 52|4@1+ (1,0) [0|15] "" XXX
 SG_ LEFT_LANE_LINE : 56|2@1+ (1,0) [0|3] "" XXX
 SG_ SET_ME_0 : 58|2@1+ (1,0) [0|3] "" XXX
 SG_ RIGHT_LANE_LINE : 60|2@1+ (1,0) [0|3] "" XXX
 SG_ SET_ME_0_2 : 62|2@1+ (1,0) [0|3] "" XXX
 SG_ LEFT_GUARD : 67|4@0+ (1,0) [0|15] "" XXX
 SG_ RIGHT_GUARD : 71|4@0+ (1,0) [0|15] "" XXX
 SG_ LEFT_BLOCKED : 75|4@0+ (1,0) [0|15] "" XXX
 SG_ RIGHT_BLOCKED : 79|4@0+ (1,0) [0|15] "" XXX
 SG_ DISTANCE_1 : 80|10@1+ (0.1,0) [0|102.3] "" XXX
 SG_ DISTANCE_2 : 96|10@1+ (0.1,0) [0|102.3] "" XXX
 SG_ DISTANCE_3 : 112|10@1+ (0.1,0) [0|102.3] "" XXX
 SG_ DISTANCE_4 : 128|10@1+ (0.1,0) [0|102.3] "" XXX
 SG_ DISTANCE_5 : 144|10@1+ (0.1,0) [0|102.3] "" XXX
 SG_ DISTANCE_6 : 160|10@1+ (0.1,0) [0|102.3] "" XXX
 SG_ DISTANCE_7 : 176|10@1+ (0.1,0) [0|102.3] "" XXX
 SG_ DISTANCE_8 : 192|10@1+ (0.1,0) [0|102.3] "" XXX

BO_ 868 CANFD_HDA_INFO_364: 16 XXX
 SG_ LinkClass : 64|3@1+ (1,0) [0|7] "" XXX
 SG_ Frwinfo : 67|3@1+ (1,0) [0|7] "" XXX
 SG_ SpeedUnit : 70|2@1+ (1,0) [0|3] "" XXX
 SG_ SPEED_LIMIT : 79|8@0+ (1,0) [0|255] "km/h" XXX
 SG_ CountryCode : 80|10@1+ (1,0) [0|1023] "" XXX
 SG_ MapSource : 91|3@1+ (1,0) [0|7] "" XXX
 SG_ TollExist : 94|2@1+ (1,0) [0|3] "" XXX
 SG_ TunnelExist : 102|2@1+ (1,0) [0|3] "" XXX

BO_ 874 BLINDSPOTS_FRONT_CORNER_2: 16 XXX
 SG_ CHECKSUM : 0|16@1+ (1,0) [0|65535] "" XXX
 SG_ COUNTER : 16|8@1+ (1,0) [0|255] "" XXX
 SG_ RIGHT_BSD : 27|1@0+ (1,0) [0|1] "" XXX
 SG_ LEFT_BSD : 28|1@0+ (1,0) [0|1] "" XXX

BO_ 896 CANFD_NAVI_STATUS_380: 24 XXX
 SG_ CAMERA_STATUS : 24|8@1+ (1,0) [0|255] "" XXX
 SG_ SPEED_LIMIT : 96|8@1+ (1,0) [0|255] "km/h" XXX

BO_ 928 TPMS: 16 XXX
 SG_ PRESSURE_FL : 39|8@0+ (1,0) [0|255] "" XXX
 SG_ PRESSURE_FR : 47|8@0+ (1,0) [0|255] "" XXX
 SG_ PRESSURE_RL : 55|8@0+ (1,0) [0|255] "" XXX
 SG_ PRESSURE_RR : 63|8@0+ (1,0) [0|255] "" XXX
 SG_ STATUS_TPMS : 66|3@0+ (1,0) [0|3] "" XXX
 SG_ UNIT : 68|2@0+ (1,0) [0|3] "" XXX

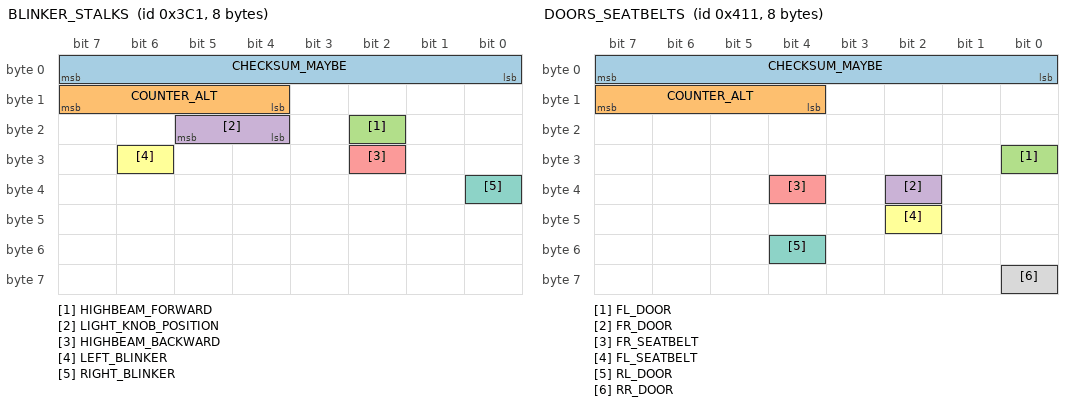
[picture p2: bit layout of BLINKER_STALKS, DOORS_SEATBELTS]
BO_ 961 BLINKER_STALKS: 8 XXX
 SG_ CHECKSUM_MAYBE : 0|8@1+ (1,0) [0|255] "" XXX
 SG_ COUNTER_ALT : 12|4@1+ (1,0) [0|15] "" XXX
 SG_ HIGHBEAM_FORWARD : 18|1@0+ (1,0) [0|1] "" XXX
 SG_ LIGHT_KNOB_POSITION : 21|2@0+ (1,0) [0|3] "" XXX
 SG_ HIGHBEAM_BACKWARD : 26|1@0+ (1,0) [0|1] "" XXX
 SG_ LEFT_BLINKER : 30|1@0+ (1,0) [0|1] "" XXX
 SG_ RIGHT_BLINKER : 32|1@0+ (1,0) [0|1] "" XXX

BO_ 995 BLINKERS_ALT: 16 XXX
 SG_ LEFT_BLINKER : 74|1@0+ (1,0) [0|1] "" XXX
 SG_ RIGHT_BLINKER : 76|1@0+ (1,0) [0|1] "" XXX
 SG_ LEFT_LAMP_ALT : 89|1@0+ (1,0) [0|1] "" XXX
 SG_ LEFT_LAMP : 90|1@0+ (1,0) [0|1] "" XXX
 SG_ RIGHT_LAMP_ALT : 91|1@0+ (1,0) [0|1] "" XXX
 SG_ RIGHT_LAMP : 92|1@0+ (1,0) [0|1] "" XXX
 SG_ NEW_SIGNAL_2 : 95|1@0+ (1,0) [0|1] "" XXX
 SG_ BLINKER_ACTIVE : 97|1@0+ (1,0) [0|1] "" XXX

BO_ 1041 DOORS_SEATBELTS: 8 XXX
 SG_ CHECKSUM_MAYBE : 0|8@1+ (1,0) [0|65535] "" XXX
 SG_ COUNTER_ALT : 12|4@1+ (1,0) [0|15] "" XXX
 SG_ FL_DOOR : 24|1@1+ (1,0) [0|1] "" XXX
 SG_ FR_DOOR : 34|1@0+ (1,0) [0|1] "" XXX
 SG_ FR_SEATBELT : 36|1@0+ (1,0) [0|1] "" XXX
 SG_ FL_SEATBELT : 42|1@0+ (1,0) [0|1] "" XXX
 SG_ RL_DOOR : 52|1@0+ (1,0) [0|1] "" XXX
 SG_ RR_DOOR : 56|1@0+ (1,0) [0|1] "" XXX

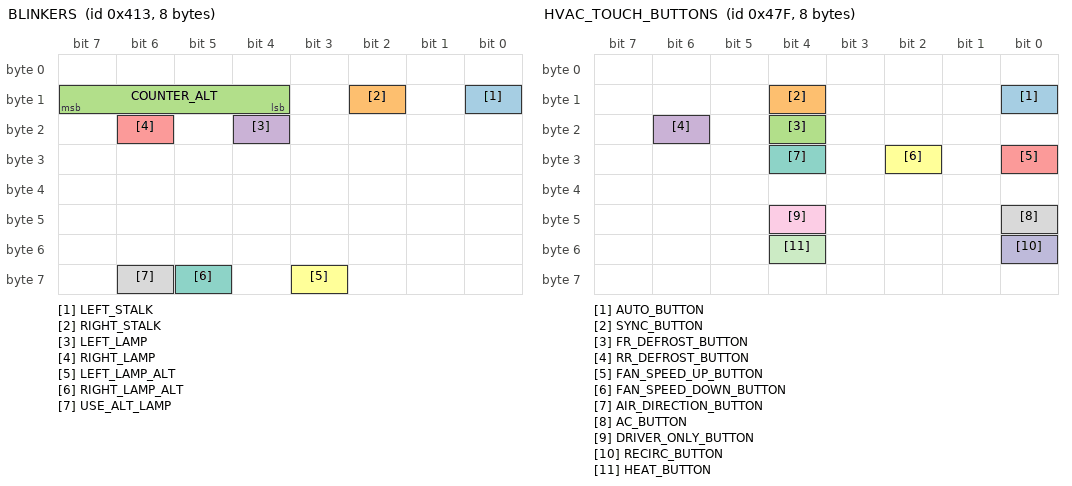
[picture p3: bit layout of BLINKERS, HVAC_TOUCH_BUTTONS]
BO_ 1043 BLINKERS: 8 XXX
 SG_ LEFT_STALK : 8|1@1+ (1,0) [0|1] "" XXX
 SG_ RIGHT_STALK : 10|1@1+ (1,0) [0|1] "" XXX
 SG_ COUNTER_ALT : 12|4@1+ (1,0) [0|15] "" XXX
 SG_ LEFT_LAMP : 20|1@1+ (1,0) [0|1] "" XXX
 SG_ RIGHT_LAMP : 22|1@1+ (1,0) [0|1] "" XXX
 SG_ LEFT_LAMP_ALT : 59|1@1+ (1,0) [0|1] "" XXX
 SG_ RIGHT_LAMP_ALT : 61|1@1+ (1,0) [0|1] "" XXX
 SG_ USE_ALT_LAMP : 62|1@1+ (1,0) [0|1] "" XXX

BO_ 1144 DRIVE_MODE: 8 XXX
 SG_ DRIVE_MODE : 0|16@1+ (1,-61611) [0|61611] "" XXX
 SG_ DRIVE_MODE2 : 28|3@1+ (1,0) [1|3] "" XXX

BO_ 1151 HVAC_TOUCH_BUTTONS: 8 XXX
 SG_ AUTO_BUTTON : 8|1@0+ (1,0) [0|1] "" XXX
 SG_ SYNC_BUTTON : 12|1@0+ (1,0) [0|1] "" XXX
 SG_ FR_DEFROST_BUTTON : 20|1@0+ (1,0) [0|1] "" XXX
 SG_ RR_DEFROST_BUTTON : 22|1@0+ (1,0) [0|1] "" XXX
 SG_ FAN_SPEED_UP_BUTTON : 24|1@0+ (1,0) [0|1] "" XXX
 SG_ FAN_SPEED_DOWN_BUTTON : 26|1@0+ (1,0) [0|1] "" XXX
 SG_ AIR_DIRECTION_BUTTON : 28|1@0+ (1,0) [0|1] "" XXX
 SG_ AC_BUTTON : 40|1@0+ (1,0) [0|1] "" XXX
 SG_ DRIVER_ONLY_BUTTON : 44|1@0+ (1,0) [0|1] "" XXX
 SG_ RECIRC_BUTTON : 48|1@0+ (1,0) [0|1] "" XXX
 SG_ HEAT_BUTTON : 52|1@0+ (1,0) [0|1] "" XXX

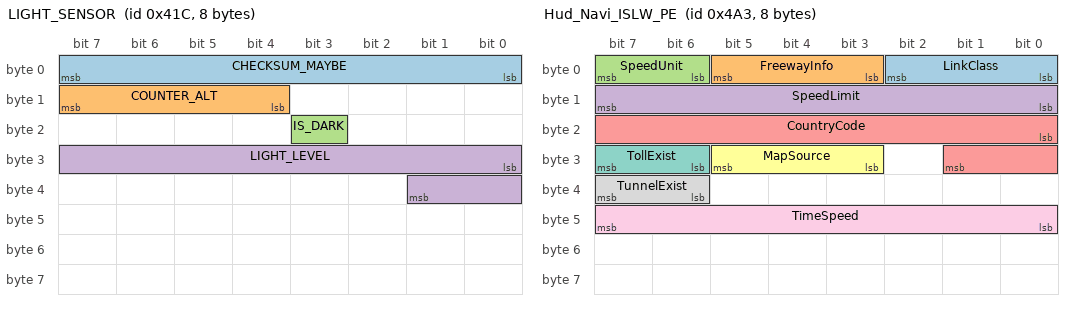
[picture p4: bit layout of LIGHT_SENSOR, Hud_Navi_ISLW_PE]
BO_ 1052 LIGHT_SENSOR: 8 XXX
 SG_ CHECKSUM_MAYBE : 7|8@0+ (1,0) [0|255] "" XXX
 SG_ COUNTER_ALT : 15|4@0+ (1,0) [0|15] "" XXX
 SG_ IS_DARK : 19|1@0+ (1,0) [0|1] "" XXX
 SG_ LIGHT_LEVEL : 24|10@1+ (1,0) [0|1023] "" XXX

BO_ 1079 TRAILER_STATUS: 8 XXX
 SG_ TRAILER_CONNECTED : 0|1@1+ (1,0) [0|1] "" XXX

BO_ 1187 Hud_Navi_ISLW_PE: 8 CGW
 SG_ LinkClass : 0|3@1+ (1,0) [0|7] ""  FR_CMR
 SG_ FreewayInfo : 3|3@1+ (1,0) [0|7] ""  FR_CMR
 SG_ SpeedUnit : 6|2@1+ (1,0) [0|3] ""  FR_CMR
 SG_ SpeedLimit : 8|8@1+ (1,0) [0|255] ""  FR_CMR
 SG_ CountryCode : 16|10@1+ (1,0) [0|1023] ""  FR_CMR
 SG_ MapSource : 27|3@1+ (1,0) [0|7] ""  FR_CMR
 SG_ TollExist : 30|2@1+ (1,0) [0|3] ""  FR_CMR
 SG_ TunnelExist : 38|2@1+ (1,0) [0|3] ""  FR_CMR
 SG_ TimeSpeed : 40|8@1+ (1,0) [0|255] ""  FR_CMR

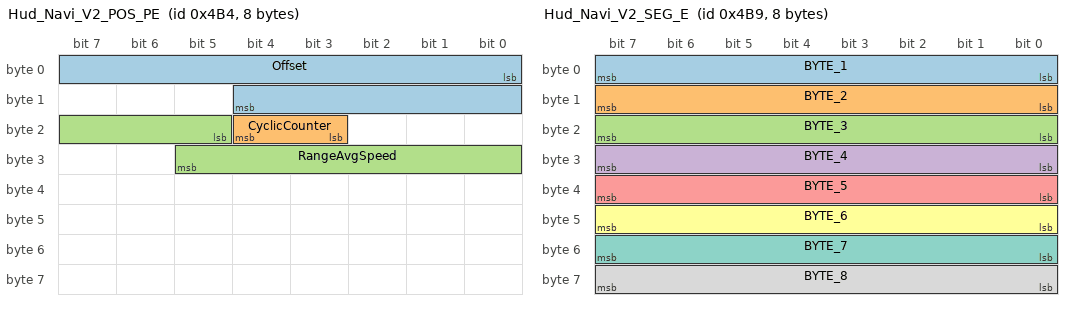
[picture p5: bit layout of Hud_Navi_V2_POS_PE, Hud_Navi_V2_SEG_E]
BO_ 1204 Hud_Navi_V2_POS_PE: 8 CGW
 SG_ Offset : 0|13@1+ (1,0) [0|8191] "m"  FR_CMR
 SG_ CyclicCounter : 19|2@1+ (1,0) [0|3] ""  FR_CMR
 SG_ RangeAvgSpeed : 21|9@1+ (1,0) [0|511] "km/h"  FR_CMR

BO_ 1208 Hud_Navi_V2_META_E: 8 CGW
 SG_ CyclicCounter : 28|2@1+ (1,0) [0|3] ""  FR_CMR
 SG_ Country_OptADAS : 40|2@1+ (1,0) [0|3] ""  FR_CMR

BO_ 1209 Hud_Navi_V2_SEG_E: 8 XXX
 SG_ BYTE_1 : 7|8@0+ (1,0) [0|255] "" XXX
 SG_ BYTE_2 : 15|8@0+ (1,0) [0|255] "" XXX
 SG_ BYTE_3 : 23|8@0+ (1,0) [0|255] "" XXX
 SG_ BYTE_4 : 31|8@0+ (1,0) [0|255] "" XXX
 SG_ BYTE_5 : 39|8@0+ (1,0) [0|255] "" XXX
 SG_ BYTE_6 : 47|8@0+ (1,0) [0|255] "" XXX
 SG_ BYTE_7 : 55|8@0+ (1,0) [0|255] "" XXX
 SG_ BYTE_8 : 63|8@0+ (1,0) [0|255] "" XXX

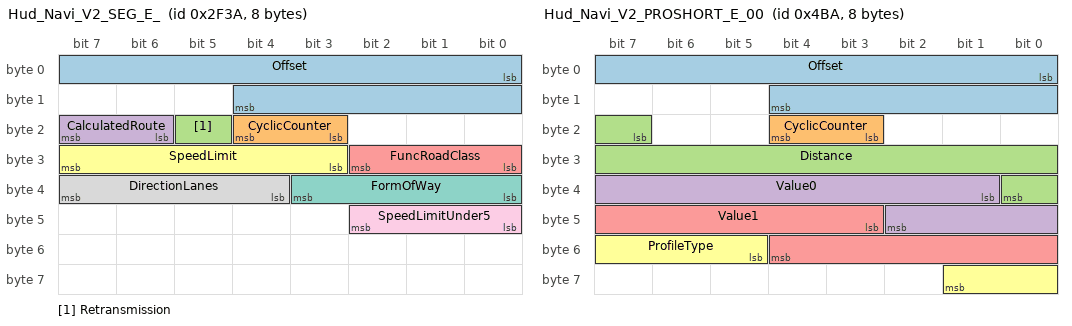
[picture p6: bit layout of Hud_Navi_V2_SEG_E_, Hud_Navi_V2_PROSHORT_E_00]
BO_ 12090 Hud_Navi_V2_SEG_E_: 8 CGW
 SG_ Offset : 0|13@1+ (1,0) [0|8191] "m"  FR_CMR
 SG_ CyclicCounter : 19|2@1+ (1,0) [0|3] ""  FR_CMR
 SG_ Retransmission : 21|1@1+ (1,0) [0|1] ""  FR_CMR
 SG_ CalculatedRoute : 22|2@1+ (1,0) [0|3] ""  FR_CMR
 SG_ FuncRoadClass : 24|3@1+ (1,0) [0|7] ""  FR_CMR
 SG_ SpeedLimit : 27|5@1+ (1,0) [0|31] ""  FR_CMR
 SG_ FormOfWay : 32|4@1+ (1,0) [0|15] ""  FR_CMR
 SG_ DirectionLanes : 36|4@1+ (1,0) [0|15] ""  FR_CMR
 SG_ SpeedLimitUnder5 : 40|3@1+ (1,0) [0|7] ""  FR_CMR

BO_ 1210 Hud_Navi_V2_PROSHORT_E_00: 8 CGW
 SG_ Offset : 0|13@1+ (1,0) [0|8191] "m"  FR_CMR
 SG_ CyclicCounter : 19|2@1+ (1,0) [0|3] ""  FR_CMR
 SG_ Distance : 23|10@1+ (1,0) [0|1023] "m"  FR_CMR
 SG_ Value0 : 33|10@1+ (1,0) [0|1023] ""  FR_CMR
 SG_ Value1 : 43|10@1+ (1,0) [0|1023] ""  FR_CMR
 SG_ ProfileType : 53|5@1+ (1,0) [0|31] ""  FR_CMR

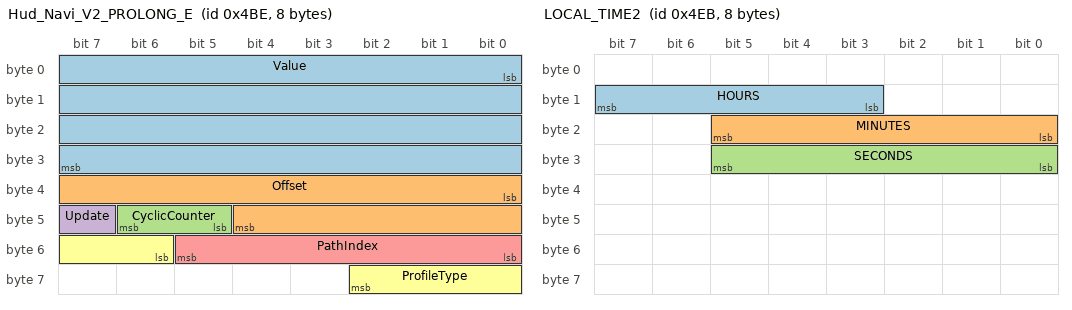
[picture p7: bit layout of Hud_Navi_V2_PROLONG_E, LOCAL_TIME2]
BO_ 1214 Hud_Navi_V2_PROLONG_E: 8 CGW
 SG_ Value : 0|32@1+ (1,0) [0|4294967295] ""  FR_CMR
 SG_ Offset : 32|13@1+ (1,0) [0|8191] "m"  FR_CMR
 SG_ CyclicCounter : 45|2@1+ (1,0) [0|3] ""  FR_CMR
 SG_ Update : 47|1@1+ (1,0) [0|1] ""  FR_CMR
 SG_ PathIndex : 48|6@1+ (1,0) [0|63] "" XXX
 SG_ ProfileType : 54|5@1+ (1,0) [0|31] ""  FR_CMR

BO_ 1240 CLUSTER_INFO: 8 XXX
 SG_ DISTANCE_UNIT : 0|1@1+ (1,0) [0|1] "" XXX

BO_ 1259 LOCAL_TIME2: 8 XXX
 SG_ HOURS : 15|5@0+ (1,0) [0|31] "" XXX
 SG_ MINUTES : 21|6@0+ (1,0) [0|63] "" XXX
 SG_ SECONDS : 24|6@1+ (1,0) [0|63] "" XXX

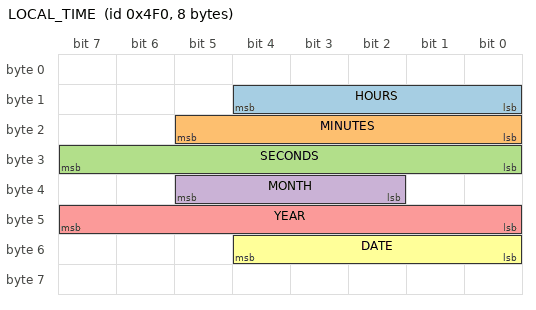
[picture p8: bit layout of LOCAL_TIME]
BO_ 1264 LOCAL_TIME: 8 XXX
 SG_ HOURS : 12|5@0+ (1,0) [0|31] "" XXX
 SG_ MINUTES : 21|6@0+ (1,0) [0|63] "" XXX
 SG_ SECONDS : 31|8@0+ (1,0) [0|59] "" XXX
 SG_ MONTH : 37|4@0+ (1,0) [0|15] "" XXX
 SG_ YEAR : 47|8@0+ (1,0) [0|255] "" XXX
 SG_ DATE : 48|5@1+ (1,0) [0|31] "" XXX

CM_ SG_ 74 IMU_Crc1Val "The data area for CRC calculation is based on the data length (DLC) of the message DB.The CRC shall be calculated over the entire data block (excluding the CRC bytes) including the user data, alive counter and Data ID- CRC Polynomial (0x1021) , Ini";
CM_ SG_ 74 IMU_AlvCnt1Val "For the first transmission request for a data element the counter shall be initialized with 0 and shall be incremented by 1 for every subsequent send request. When the counter reaches the maximum value(0xFF), then it shall restart with 0 for the next s";
CM_ SG_ 74 IMU_YawSigSta "This signal indicates failure status of yaw rate signal and yaw rate sensing element.0000B : No failure xxx1B : IMU_Yawrate_failurexx1xB : Initialization is runningx1xxB : Reserved1xxxB : ReservedThis signal represents the physica";
CM_ SG_ 74 IMU_LatAccelSigSta "This signal indicates failure status of lateral acceleration signal and sensing element.0000B : No failurexxx1B : IMU_Lateral acceleration failurexx1xB : Initialization is runningx1xxB : Reserved1xxxB : ReservedThis signal represe";
CM_ SG_ 74 IMU_AcuRstSta "This signal indicates the status of IMU.0000B : Normal mode xxx1B : IMU Reset modexx1xB : Reservedx1xxB : Reserved1xxxB : ReservedIf ACU reset is required, ACU will send IMU RESET bit(XXX1B) up to 30 times and perform a reset. If ";
CM_ SG_ 74 IMU_YawRtVal "This signal indicates Information regarding yaw rate.physical range : -163.84..163.83 ˚/s = 0000H..FFFEhConversion : (PH) = ((HEX)-8000H)*0.005[˚/s/digit] = (HEX)*0.005[˚/s/digit] - 163.84[˚/s] ";
CM_ SG_ 74 IMU_LatAccelVal "This signal indicates Information regarding lateral acceleration.physical range : -4.1768g..4.1765g = 0000H..FFFEhConversion : (PH) = ((HEX)-8000H)*0.000127465[g/digit] = (HEX)*0.000127465[g/digit] - 4.17677312[g]";

CM_ SG_ 96 BRAKE_PRESSURE "User applied brake pedal pressure. Ramps from computer applied pressure on falling edge of cruise. Cruise cancels if !=0";
CM_ SG_ 96 AUTO_HOLD "AVH status. Indicates whether the vehicle is held with the hydraulic service brake";
CM_ SG_ 96 AVH_I_LAMP "AutoHold indicator lamp state. 0 on, 1 off";
CM_ SG_ 96 AVH_LAMP "AutoHold mode and lamp state. 0 off, 1 failure, 2 active, 3 ready";
CM_ SG_ 101 BRAKE_POSITION "User applied brake pedal position, max is ~700. Signed on some vehicles";
CM_ BO_ 203 "Known in official DBC as ADAS_CMD_35_10ms";
CM_ SG_ 203 ADAS_AngleActiveStat "ADAS Active AngleControlInterface State";
CM_ SG_ 203 ADAS_AngleActiveStat_Lv2 "ADAS Active AngleControlInterface Level 2 State";
CM_ SG_ 203 ADAS_AngleReq "(LFA) ADAS Steering Angle Request Value";
CM_ SG_ 203 ADAS_AngleTorqueGain "(LFA) ADAS AngleControlInterface Angle Torque Reduction Gain Value";
CM_ SG_ 203 FCA_ESA_ActiveStat "FCA_ESA Active State";
CM_ SG_ 203 FCA_ESA_ToqueGain "FCA_ESA Torque Boost Gain Value";
CM_ SG_ 229 ESC_YawSigSta "ESC_YawSigSta";
CM_ SG_ 229 ESC_LatAccelSigSta "ESC_LatAccelSigSta";
CM_ SG_ 229 ESC_LongAccelSigSta "ESC_LongAccelSigSta";
CM_ SG_ 229 ESC_YawRtVal "ESC_YawRtVal";
CM_ SG_ 229 ESC_LatAccelVal "ESC_LatAccelVal";
CM_ SG_ 229 ESC_LongAccelVal "ESC_LongAccelVal";
CM_ SG_ 234 WarningLamp "The signal indicates the ststus of the MDPS Warning lamp";
CM_ SG_ 234 Type "Information regarding the type of MDPS. (C-MDPS / R-MDPS / SbW)";
CM_ SG_ 234 EngineIdleRpmReq "This signal indicates the request status for engine idle rpm up according to MDPS fast rotation.";
CM_ SG_ 234 VSM_Stat "This signal indicates whether the VSM function of MDPS is plugged in or not.";
CM_ SG_ 234 VSM_DefectiveStat "Information regarding the MDPS defective, Indication For VSM";
CM_ SG_ 234 VSM_SignalStat "Information indicating VSM signal status";
CM_ SG_ 234 PA_Stat "This signal indicates whether the PA function of MDPS is plugged in or not.";
CM_ SG_ 234 PA_ModeStat "This signal indicates the status of the PA steering function.";
CM_ SG_ 234 PA_CanFailStat "This Signal should be used by only PA This signal indicates whether the MDPS is defective in PA cooperation control.  This signal is set as '1' only when MDPS Detects CAN Failure(TIMEOUT, Signal Error) of PA CAN Message";
CM_ SG_ 234 LKA_Stat "This signal indicates whether the LKA function of MDPS is plugged in or not.";
CM_ SG_ 234 LKA_ToiActiveStat "This flag is set to 1 in response to the LKA Controller requesting the activation of the torque interface and set back to 0 in response to the LKA Controller requesting the de-activation of the torque interface.";
CM_ SG_ 234 LKA_ToiUnavailStat "This is a flag that is set when the MDPS is not faulty, but is temporarily unable to activate the TOI due to steering torque limiting e.g. when the supply voltage is too low.";
CM_ SG_ 234 LKA_ToiFaultStat "This fault flag is set when a fault within the MDPS system has been detected such that the LKA TOI can no longer function. CAN failures, internal MDPS failures, and LKA controller logic failures are all reported by this flag. Failures reported by the LKA";
CM_ SG_ 234 LKA_ToiFailStat "This fault flag is set whilst the MDPS TOI is in a fail state and has not yet recovered from it. This could either be due to an MDPS detected fault (as communicated by the LKA_ToiFaultStat' flag) or an LKA detected fault (as communicated by the LKA_";
CM_ SG_ 234 ResetStat "Information regarding the state of reset";
CM_ SG_ 234 SteerMode "This signal indicates flex steer parameter value in MDPS. For information about flex steer mode set by user, refer to MDPS_FlxStrSta signal.";
CM_ SG_ 234 OutTorque "MDPS column torque this signal has direction information. '+' Value means Counter clock wise rotation. '-' value means Clock wise rotation.";
CM_ SG_ 234 VSM_Stat "Information of VSM Torque Intervention Act Response";
CM_ SG_ 234 ReprogramStat "Information regarding the reprogram state";
CM_ SG_ 234 SteerTorqueSensor "Steering torque sensor value Physical Value > 0: Left Direction (CCW) Physical Value < 0: Right Direction (CW) this signal has direction information. '+' Value means Counter clock wise rotation. '-' value means Clock wise rotation.";
CM_ SG_ 234 PA_SteerAngle "This value is used to inform PA of a compensated steering wheel angle by MDPS. The signal is signed 16bits. (PH) = (HEX) �� 0.1 (for 0 < HEX �� 32767)  or = (HEX - 65536) �� 0.1 (for HEX > 32767) [Deg] this signal has direction information. '+' V";
CM_ SG_ 234 LoamStat "The signal represent status of the LOAM(Loss Of Assist Mitigation) Mode";
CM_ SG_ 234 HDPSwVer "This signal indicates HDP-MDPS Control Requirement Spec Version";
CM_ SG_ 234 ADAS_ActiveStat "State for angle control";
CM_ SG_ 234 ADAS_AciPlugStat "This signal indicates whether the ADASAci function of MDPS is plugged in or not.";
CM_ SG_ 234 ADAS_AciPlugStat "MDPS Fault Status for HDP Function";
CM_ SG_ 234 EstSteerAngle "This value is used to inform of a compensated steering wheel angle by MDPS. The signal is signed 16bits, and made by motor position sensor. (PH) = (HEX) * 0.1 (for 0 < HEX <= 32767) or = (HEX - 65536) * 0.1 (for HEX > 32767) [Deg].";
CM_ SG_ 234 ADAS_ActiveStat_Lv2 "States for angle control (LV2)";
CM_ SG_ 234 ADAS_AciFault_Lv2 "MDPS Fault Status for LV2 Angle Control Function";
CM_ SG_ 234 TPA_Stat "This signal indicates whether the TPA function of MDPS is plugged in or not.";
CM_ SG_ 234 TPA_CanFailStat "This Signal should be used by only TPA. This signal indicates whether the MDPS is defective in TPA cooperation control. This signal is set as '1' only when MDPS Detects CAN Failure(TIMEOUT, Signal Error) of TPA CAN Message";
CM_ SG_ 234 TPA_ModeStat "This signal indicates the status of the TPA steering function.";
CM_ SG_ 234 TPA_SteerAngle "This value is used to inform TPA of a compensated steering wheel angle by MDPS. The signal is signed 16bits. (PH) = (HEX) * 0.1 (for 0 < HEX <= 32767) or = (HEX - 65536) * 0.1 (for HEX > 32767) [Deg]";
CM_ BO_ 272 "Alternative LKAS message, used on cars such as 2023 Ioniq 6, 2nd gen Kona. Matches LKAS except size is 32 bytes";
CM_ SG_ 272 ToiFltSta "This fault flag is set when a fault in the LKA system has been detected by the LKA ECU such that LKA can no longer function. CAN failures, internal video ECU failures, hard-wired component (e.g. master switch) failures and other system logic failures are";
CM_ SG_ 272 LKA_RcgSta "Angle control cars: 3 when LKA is generally available, goes to 0 during changes with LFA";
CM_ SG_ 272 ADAS_AngleReq "(LKAS) ADAS Steering Angle Request Value; Capped at 176.7; tracks MDPS->STEERING_ANGLE when not engaged, not STEERING_SENSORS->STEERING_ANGLE";
CM_ SG_ 272 ADAS_AngleTorqueGain "(LKAS) ADAS AngleControlInterface Angle Torque Reduction Gain Value";
CM_ BO_ 282 "Sent by the camera containing DAW (Driver Attention Warning) information and information about HBA (High Beam Assist).";
CM_ BO_ 298 "This message controls steering and alerts regarding lateral control. Formerly known as LFA.";
CM_ SG_ 282 HBA_SysOptSta "HBA System Option Information to Lamp Controller";
CM_ SG_ 282 HBA_SysSta "This signal indicates the status of High Beam Assist system.";
CM_ SG_ 282 HBA_IndLmpReq "HBA System Indicator Lamp Status";
CM_ SG_ 282 FCA_Equip_MFC "FCA Sensor Type";
CM_ SG_ 282 HBA_OptUsmSta "HBA Option USM Status";
CM_ SG_ 282 DAW_LVDA_PUDis "Message for displaying LVDA(Leading Vehicle Departure Alert) Warning";
CM_ SG_ 282 DAW_LVDA_OptUsmSta "LVDA USM state";
CM_ SG_ 282 DAW_OptUsmSta "This signal represents the lastest DAW ON/OFF value of USM.";
CM_ SG_ 282 DAW_SysSta "This signal represents Attention Assist System Status or Attention Level.";
CM_ SG_ 282 DAW_WrnMsgSta "0x1 value requests DAW Rest recommend warning message popup at CLU. 0x2 value requests HDA/LFA Hands-Off call at TMS.";
CM_ SG_ 282 DAW_TimeRstReq "This signal requests CLU 'Last Break Time' Reset. DAW send '0x1' when detecting driver's rest.";
CM_ SG_ 282 DAW_SnstvtyModRetVal "This signal represents the feedback value of the current ADAS warning timing.";
CM_ SG_ 282 SCCEquipStat "This signal indicates equipment for SCC";
CM_ SG_ 282 DASMapMsg "This signal indicates an ADAS map message request from FR_CMR to H_U. Each bit indicates the request messages as follows. - Bit 0 : H_U_NAVI_V2_STUB_E - Bit 1 : HU_NAVI_V2_PROSHORT_E_00 (곡률) - Bit 2 : HU_NAVI_V2_PROSHORT_E_00 (곡률 외 정보)";
CM_ SG_ 282 SwVer1 "This signal indicates a major version of FR_CMR software. If FR_CMR software version is A.00, 'A' and '00' mean major and minor version respectively.";
CM_ SG_ 282 SwVer2 "This signal indicates a minor version of FR_CMR software. If FR_CMR software version is A.00, 'A' and '00' mean major and minor version respectively.";
CM_ SG_ 298 NEW_SIGNAL_4 "todo: figure out why always set to 9";
CM_ SG_ 298 LKA_OptUsmSta "LKA_OptionUsmStatus ##2G##LDW_LKA - LKA11 - CF_LKA_Opt_USM";
CM_ SG_ 298 LKA_RcgSta "LKA_RecognitionStatus ##2G##LDW_LKA - LKA11 - CF_LKA_LaneRecogState";
CM_ SG_ 298 LKA_LHLnWrnSta "LKA_LHLaneWarningStatus ##2G##LDW_LKA - LKA11 - CF_LKA_LHWarning";
CM_ SG_ 298 LKA_RHLnWrnSta "LKA_RHLaneWarningStatus ##2G##LDW_LKA - LKA11 - CF_LKA_RHWarning";
CM_ SG_ 298 LKA_HndsoffSnd "LKA_HandsoffSound ##2G##LDW_LKA - LKA11 - CF_LKA_HandsOff_Snd";
CM_ SG_ 298 LKA_StrSnd "LKA_SteeringSound ##2G##LDW_LKA - LKA11 - CF_LKA_Steer_Snd";
CM_ SG_ 298 LKA_ICON "LKA_SystemIndicatorRequest ##2G##LDW_LKA - LKA11 - CF_LKA_SymbolState";
CM_ SG_ 298 ADAS_StrTqReqVal "This is the driver torque overlay demand value. A negative value represents a torque that would accelerate the steering wheel in a clockwise direction. This signal is always zero whilst the TOI is inactive.";
CM_ SG_ 298 ADAS_ActToiSta "This is a flag that is set to 1 when requesting the steering to activate the torque overlay interface (TOI).  This must be done before an attempt is made to request non-zero steering torque overlay.";
CM_ SG_ 298 ADAS_ToiFltSta "This fault flag is set when a fault in the LKA system has been detected by the LKA ECU such that LKA can no longer function. CAN failures, internal video ECU failures, hard-wired component (e.g. master switch) failures and other system logic failures are";
CM_ SG_ 298 LKA_SysWrn "A signal that provides additional information on the operation of the LKA system for the HMI to display to the driver. This includes additional fault information, reasons for unavailability of the system and additional warnings like the hands-off warning";
CM_ SG_ 298 FCA_LS_WrnSta "(Reverse Engineered) This signal was observed while ELK was taking over to prevent a blind spot collision.";
CM_ SG_ 298 LKA_UsmMod "This signal indicates LKA USM Mode";
CM_ SG_ 298 ELK_SymbDisp "Emergency Lane-Keeping";
CM_ SG_ 298 ADAS_Damping_Gain "ADAS Damping Gain for MDPS";
CM_ SG_ 352 SET_ME_9 "has something to do with AEB settings";
CM_ SG_ 373 ACCEnable "Likely a copy of CAN's TCS13->ACCEnable";
CM_ SG_ 373 DriverBraking "Likely derived from BRAKE->BRAKE_POSITION";
CM_ SG_ 373 DriverBrakingLowSens "Higher threshold version of DriverBraking";
CM_ SG_ 373 PROBABLY_EQUIP "aeb equip?";
CM_ BO_ 416 "SCC_CONTROL, this is the signal responsible for longitudinal control and a few warnings related to it.";
CM_ SG_ 416 ObjectDistance "This signal provides the distance to the in lane detected SCC object regarding to the own vehicle. - 자차선상의 전방 인식된 물체와의 거리";
CM_ SG_ 416 ObjectRelativeSpeed "This signal provides the relative speed to the in lane detected SCC object regarding to the own vehicle. - 자차선상의 전방 인식된 물체와 자차간 상대 속도";
CM_ SG_ 416 ObjectLateralPosition "This signal provides the lateral position of the detected SCC object regarding to the own vehicle.  The position of the SCC object on the left side in driving direction of the vehicle longitudinal axis correlates with a negative signal value.  Thus an";
CM_ SG_ 416 SysFailStat "This signal is evaluated by the driver information device to release the failure information to the driver. If this signal is set to anything other than 0, the TCS/ESC shall ignore any requests from SCC - 시스템 고장 발생 정보용 - 해당 값";
CM_ SG_ 416 MainStat "This signal specifies the status of a Main switch of SCC system - Main swith 에 의한 SCC ON/OFF 상태 정보";
CM_ SG_ 416 OperationStat "The signal ACCmode specifies the operational mode of SCC - ACC 작동 상태 정보(off&ready / active / override / shut off)";
CM_ SG_ 416 TakeoverReq "The Take-over Request supports the driver to identify the limits of the SCC control. Reasons for such a request may be: - Deceleration capability insufficient for the current situation. Clutch actuation by the driver is necessary to avoid stopping of t";
CM_ SG_ 416 InfoDisplay "This signal carries information that indicates below 4 signals. (1) SCC Mode display (2) CC Mode display (3) Object disapearing display (4) Go notifying display";
CM_ SG_ 416 AlertDisplay "This signal carries the information which message shall be displayed to the driver  when the SCC must be disengaged by the system or cann’t be engaged. A signal value unequal 00H is repeated for 5 messages cycles in order to ensure it appears for at";
CM_ SG_ 416 ObjectDistanceLevel "If a in-path object is recognized by SCC, the driver should be informed.";
CM_ SG_ 416 DistanceGapSet "The desired time gap from which a following distance is extracted has to be presented to the driver at least if the value changes.  The representation of the information depends on the display concept. - 전방 차량과의 거리 setting 정보";
CM_ SG_ 416 NSCC_AutoSetStat "This is information if Auto Set Speed Control is enabled or not.";
CM_ SG_ 416 SCC_TrgtSpdSetVal "The desired vehicle speed for free cruising has to be displayed all the time SCC is under active control. ※This signal can be sent in km/h or MPH according to the “SPEED_UNIT” signal (See CLU1 message). SPEED_UNIT = 0 : [km/h], SPEED_UNIT = 1 : [";
CM_ SG_ 416 NSCC_OperationStat "This signal describes the operational status of NSCC-Z/C/R function.   NSCC-Z/C/R  작동 상태 정보(off/ready/active)";
CM_ SG_ 416 NSCC_MainStat "This signal describes the on/off status of NSCC-Z/C/R and HDA Auto-set function.   NSCC-Z/C/R  and HDA auto-set on/off 상태 정보";
CM_ SG_ 416 ObjectStat "This signal represents the state of in-path object and information of controllable state. - 자차선상의 전방 차량 인식 여부 및 제어 가능 상태 정보";
CM_ SG_ 416 SensitiveMode "This signal is SCC sensitive set mode switch info return value to cluster - SCC 민감도 설정 관련 USM 설정 스위치 정보의 리턴 값";
CM_ SG_ 416 NSCC_AutoSetSpeedStat "This is information if Auto Set Speed Control is updated or not.";
CM_ SG_ 416 NSCC_InfoDisplay "This signal shows the cluster pop-up for NSCC Information.";
CM_ SG_ 416 AccelRequest "This signal represents the SCC acceleration request after jerk limit. - Jerk limit를 거친 SCC 의 요구 가속도/감속도 값";
CM_ SG_ 416 AccelRequestRaw "This signal represents the SCC acceleration request before jerk limit.  - Jerk limit를 거치지 않은 SCC 의 요구 가속도/감속도 값";
CM_ SG_ 416 JerkUpperLimit "This signal is the value of positive jerk limit request.  - SCC 의 요구 가속도 상승변화율 제한 값";
CM_ SG_ 416 JerkLowerLimit "This signal is the value of negative jerk limit request.  - SCC 의 요구 가속도 하강변화율 제한 값";
CM_ SG_ 416 AccelLimitBandUpper "This signal is the upper value of acceleration limit band. - SCC 의 가속도 제어 허용 범위 상한 참고값";
CM_ SG_ 416 AccelLimitBandLower "This signal is the lower value of acceleration limit band. - SCC 의 가속도 제어 허용 범위 하한 참고값";
CM_ SG_ 416 StopReq "A control request flag for vehicle stop. SCC expects vehicle to be controlled to a complete stop and hold its state. - SCC 해제 상황 발생시 차량 정차 유지를 위한 제동 요청 신호";
CM_ SG_ 416 EngineStopReq "This signal indicates engine state request of SCC.  - 0x0 : SCC deactive or SCC off  - 0x1 : 'ISG Stop' Possible  - 0x2 : 'ISG Start or Maintain Engine Run' Request  - 0x3 : Reserved";
CM_ SG_ 416 TargetDistance "This signal provides the target distance for SCC fallowing control. - SCC 거리 제어를 위한 목표 차간 거리 정보";
CM_ SG_ 416 VSetDis "set speed in display units";
CM_ BO_ 437 "Sent by the camera containing lane and lead information.";
CM_ SG_ 437 LeftLnQualStat "This signal indicates the quality of left line.";
CM_ SG_ 437 LeftLnDptStat "This signal indicates the lane departure status of left line.";
CM_ SG_ 437 LeftLnPosition "This signal outputs the position of left line from camera center.";
CM_ SG_ 437 LeftLnHeadingAngle "This signal outputs the heading angle of left line.";
CM_ SG_ 437 LeftLnCurvature "This signal outputs the curvature of left line.";
CM_ SG_ 437 RightLnQualStat "This signal indicates the quality of right line.";
CM_ SG_ 437 RightLnDptStat "This signal indicates the lane departure status of right line.";
CM_ SG_ 437 RightLnPosition "This signal outputs the position of right line from camera center.";
CM_ SG_ 437 RightLnHeadingAngle "This signal outputs the heading angle of right line.";
CM_ SG_ 437 RightLnCurvature "This signal outputs the curvature of right line.";
CM_ SG_ 437 ID_CIPV "Valid Object = 1 to 255 - ID detected by front camera can vary depending on vehicle environment. - Additional logic would be required to apply this signal for ISG.";
CM_ SG_ 437 Relative_Velocity "+ : Preceding, - : Oncoming - Velocity detected by front camera can vary depending on vehicle environment. - Additional logic would be required to apply this signal for ISG. - Confirmaiton by Autonomous Driving Engineering Team is required to use ID_C";
CM_ SG_ 442 BCW_LeftIndSta "Left blind-spot indicator. When a vehicle is detected, the BCW light on the side mirror illuminates. When the blinker is also on, the BCW light flashes on both the dash and the mirror to alert the driver.";
CM_ SG_ 442 BCW_RightIndSta "Right blind-spot indicator. When a vehicle is detected, the BCW light on the side mirror illuminates. When the blinker is also on, the BCW light flashes on both the dash and the mirror to alert the driver.";
CM_ SG_ 416 SCC_ObjSta "state of in-path object and information of controllable state.";
CM_ SG_ 480 NEW_SIGNAL_5 "todo: figure out why always set to 1";
CM_ BO_ 506 "Sent by the camera containing speed limit information. ISLW stands for Intelligent Speed Limit Warning, and ISLA is Intelligent Speed Limit Assist. it also contains road sign information.";
CM_ SG_ 506 ISLW_OptUsmSta "ISLW option information";
CM_ SG_ 506 SysSta "Validity of ISLW information";
CM_ SG_ 506 NoPassingInfoDis "This signal indicates additional information of ISLW. For example no passing.";
CM_ SG_ 506 OvrlpSignDis "indicates presence of Overlap sign";
CM_ SG_ 506 CluSpeedLimit "Main Speed Information for cluster display in main page(0x1~0xFCH: 1*(HEX VALUE) [KPH or MPH :Reference signal is  CF_Clu_SPEED_UNIT of CLU])";
CM_ SG_ 506 NavSpeedLimit "Main Speed information for navigation display in main page(0x1~0xFCH: 1*(HEX VALUE) [KPH or MPH :Reference signal is  Navi_SpdUnit of Navigation)";
CM_ SG_ 506 SubCondinfoSta1 "Indicates 1st conditional traffic sign status";
CM_ SG_ 506 SubCondinfoSta2 "Indicates 2nd conditional traffic sign status";
CM_ SG_ 506 SpdCluSubMainDis "Main Speed Information for cluster display in ISLW detail page";
CM_ SG_ 506 SpdCluDisSubCond1 "Indicates conditional speed limit/no passing of 1st conditional traffic sign for Cluster in ISLW Detail page";
CM_ SG_ 506 SpdCluDisSubCond2 "Indicates conditional speed limit/no passing of 2nd conditional traffic sign for Cluster in ISLW Detail page";
CM_ SG_ 506 SpdNaviSubMainDis "Main Speed Information for NAVI display in ISLW detail page";
CM_ SG_ 506 SpdNaviDisSubCond1 "Indicates conditional speed limit/no passing of 1st conditional traffic sign for NAVI in ISLW Detail page";
CM_ SG_ 506 SpdNaviDisSubCond2 "Indicates conditional speed limit/no passing of 2nd conditional traffic sign for NAVI in ISLW Detail page";
CM_ SG_ 506 SpdwOffst "This is a ISLA speed with offset to change the set speed of MSLA/CC/SCC.Unit (kph or mph) refers to cluster signal: CLU_SpdUnitTyp@CLU_01_20ms";
CM_ SG_ 506 SwIgnoreReq "This is a signal requesting to ignore the -(SET) or +(SET) switch input of the driver.";
CM_ SG_ 506 SpdChgReq "This is a signal requesting to change the set speed of MSLA/CC/SCC to the ISLA speed.";
CM_ SG_ 506 SpdWrn "This is a warning signal when VANZ exceeds the speed limit.";
CM_ SG_ 506 IcyWrn "This is a warning signal when the snow or ice sign is recognized when it is less than 4 'C.";
CM_ SG_ 506 SymFlashMod "This is a signal for the flashing mode of the symbol.";
CM_ SG_ 506 Popup "This is a signal for ISLA pop-up.";
CM_ SG_ 506 ISLA_OptUsmSta "This is a ISLA option USM signal set by the driver.";
CM_ SG_ 506 OffstUsmSta "This is a signal for offset speed set by the driver. Unit (kph or mph) refers to cluster signal: CLU_SpdUnitTyp@CLU_01_20ms";
CM_ SG_ 506 AutoUsmSta "This is a signal for ISLA AUTO USM set by the driver.";
CM_ SG_ 506 Country "This is a signal for categorizing countries";
CM_ SG_ 506 ROAD_SIGNS "This is a signal for additional sign";
CM_ SG_ 506 SchoolZone "This is a signal for School Zone";
CM_ SG_ 676 LEFT_LANE_LINE "Left lane line confidence";
CM_ SG_ 676 RIGHT_LANE_LINE "Right lane line confidence";
CM_ SG_ 687 HOD_Dir_Status "This signal indicates the status of hands on/off";
CM_ BO_ 698 "Sent by the camera containing information about vehicles in front of us. IFS stands for Intelligent Front-lighting System, and this signal provides the information necessary for it to operate.";
CM_ SG_ 698 Status "This is IFS system status needed for operate the IFS function of headlamp highbeam";
CM_ SG_ 698 VehNumVal "This is number of vehicles detected from camera";
CM_ SG_ 698 ILLAmbtSta "This signal is status of the ambient brightness 0x0 is bright condition (HighBeam off), 0x1 is dark condition (None)";
CM_ SG_ 698 VehLeftAngl1Val "This is left angle of vehicle 1 Deg = (HEX)*0.1-25";
CM_ SG_ 698 VehRightAngl1Val "This is right angle of vehicle 1 Deg = (HEX)*0.1-25";
CM_ SG_ 698 VehLeftAngl2Val "This is left angle of vehicle 2 Deg = (HEX)*0.1-25";
CM_ SG_ 698 VehDst1Val "VehicleDistance1Value";
CM_ SG_ 698 VehRightAngl2Val "This is right angle of vehicle 2 Deg = (HEX)*0.1-25";
CM_ SG_ 698 VehLeftAngl3Val "This is left angle of vehicle 3 Deg = (HEX)*0.1-25";
CM_ SG_ 698 VehRightAngl3Val "This is right angle of vehicle 3 Deg = (HEX)*0.1-25";
CM_ SG_ 698 VehLeftAngl4Val "This is left angle of vehicle 4 Deg = (HEX)*0.1-25";
CM_ SG_ 698 VehRightAngl4Val "This is right angle of vehicle 4 Deg = (HEX)*0.1-25";
CM_ SG_ 698 VehLeftAngl5Val "This is left angle of vehicle 5 Deg = (HEX)*0.1-25";
CM_ SG_ 698 VehRightAngl5Val "This is right angle of vehicle 5 Deg = (HEX)*0.1-25";
CM_ SG_ 698 VehLeftAngl6Val "This is left angle of vehicle 6 Deg = (HEX)*0.1-25";
CM_ SG_ 698 VehRightAngl6Val "This is right angle of vehicle 6 Deg = (HEX)*0.1-25";
CM_ SG_ 698 VehLeftAngl7Val "This is left angle of vehicle 7 Deg = (HEX)*0.1-25";
CM_ SG_ 698 VehRightAngl7Val "This is right angle of vehicle 7 Deg = (HEX)*0.1-25";
CM_ SG_ 698 VehLeftAngl8Val "This is left angle of vehicle 8 Deg = (HEX)*0.1-25";
CM_ SG_ 698 VehRightAngl8Val "This is right angle of vehicle 8 Deg = (HEX)*0.1-25";
CM_ SG_ 698 VehLeftAngl9Val "This is left angle of vehicle 9 Deg = (HEX)*0.1-25";
CM_ SG_ 698 VehRightAngl9Val "This is right angle of vehicle 9 Deg = (HEX)*0.1-25";
CM_ SG_ 698 VehLeftAngl10Val "This is left angle of vehicle 10 Deg = (HEX)*0.1-25";
CM_ SG_ 698 VehRightAngl10Val "This is right angle of vehicle 10 Deg = (HEX)*0.1-25";
CM_ SG_ 698 VehDst2Val "VehicleDistance2Value";
CM_ SG_ 698 VehDst3Val "VehicleDistance3Value";
CM_ SG_ 698 VehDst4Val "VehicleDistance4Value";
CM_ SG_ 698 VehDst5Val "VehicleDistance5Value";
CM_ SG_ 698 VehDst6Val "VehicleDistance6Value";
CM_ SG_ 698 VehDst7Val "VehicleDistance7Value";
CM_ SG_ 698 VehDst8Val "VehicleDistance8Value";
CM_ SG_ 698 VehDst9Val "VehicleDistance9Value";
CM_ SG_ 698 VehDst10Val "VehicleDistance10Value";
CM_ SG_ 736 MAX_SPEED "Display units. Restricts car from driving above this speed unless accelerator pedal is depressed beyond pressure point";
CM_ BO_ 866 "Contains signals with detailed lane line information. Used by ADAS ECU on HDA 2 vehicles to operate LFA. Used on cars that use message 272.";
CM_ SG_ 866 LEFT_LANE_LINE "Left lane line confidence";
CM_ SG_ 866 RIGHT_LANE_LINE "Right lane line confidence";
CM_ SG_ 961 COUNTER_ALT "only increments on change";
CM_ SG_ 1041 COUNTER_ALT "only increments on change";
CM_ BO_ 1043 "Lamp signals do not seem universal on cars that use LKAS_ALT, but stalk signals do.";
CM_ SG_ 1043 COUNTER_ALT "only increments on change";
CM_ SG_ 1043 USE_ALT_LAMP "likely 1 on cars that use alt lamp signals";
VAL_ 53 GEAR 0 "P" 5 "D" 6 "N" 7 "R";
VAL_ 64 GEAR 0 "P" 5 "D" 6 "N" 7 "R";
VAL_ 69 GEAR 0 "P" 5 "D" 6 "N" 7 "R";
VAL_ 96 TRACTION_AND_STABILITY_CONTROL 0 "On" 5 "Limited" 1 "Off";
VAL_ 96 AUTO_HOLD 0 "No apply" 1 "Vehicle is held by the service brake" 2 "Being released" 3 "Error Indicator";
VAL_ 96 AVH_I_LAMP 0 "Lamp on" 1 "Lamp off" 2 "Reserved" 3 "Reserved";
VAL_ 96 AVH_LAMP 0 "AVH off" 1 "AVH failure" 2 "AVH active" 3 "AVH ready" 4 "Reserved" 5 "Reserved" 6 "Reserved" 7 "Reserved";
VAL_ 112 GEAR 0 "P" 5 "D" 6 "N" 7 "R";
VAL_ 203 ADAS_AngleActiveStat 0 "INIT" 1 "INACTIVE" 2 "ACTIVE35(ACTIVE)" 3 "ACTIVE33(Redundancy)" 4 "RESERVED" 5 "RESERVED" 6 "RESERVED" 7 "RESERVED" 8 "RESERVED" 9 "RESERVED" 10 "RESERVED" 11 "RESERVED" 12 "RESERVED" 13 "RESERVED" 14 "RESERVED" 15 "RESERVED";
VAL_ 203 ADAS_AngleActiveStat_Lv2 0 "INIT" 1 "INACTIVE" 2 "ACTIVE35(ACTIVE)" 3 "RESERVED" 4 "RESERVED" 5 "RESERVED" 6 "RESERVED" 7 "RESERVED" 8 "RESERVED" 9 "RESERVED" 10 "RESERVED" 11 "RESERVED" 12 "RESERVED" 13 "RESERVED" 14 "RESERVED" 15 "RESERVED";
VAL_ 203 ADAS_AngleReq 0 "0x0x000~0x3FFF:Real Values" 16383 "0x0x000~0x3FFF:Real Values";
VAL_ 203 ADAS_AngleTorqueGain 0 "0x0x00~0xFA:Real Values" 250 "0x0x00~0xFA:Real Values" 251 "RESERVED" 252 "RESERVED" 253 "RESERVED" 254 "RESERVED" 255 "RESERVED";
VAL_ 203 FCA_ESA_ActiveStat 0 "Inactive" 1 "Active" 2 "RESERVED" 3 "RESERVED";
VAL_ 203 FCA_ESA_ToqueGain 0 "0x0x00~0xFA:Real Values" 250 "0x0x00~0xFA:Real Values" 251 "RESERVED" 252 "RESERVED" 253 "RESERVED" 254 "RESERVED" 255 "RESERVED";
VAL_ 234 WarningLamp 0 "MDPS Malfunction Warning lamp OFF" 1 "MDPS Malfunciton Warning lamp BLANKING(2Hz)" 2 "MDPS Malfunction Warning lamp ON" 3 "MDPS Malfunction Warning lamp BLANKING(1Hz)" 4 "RESERVED" 5 "RESERVED" 6 "RESERVED" 7 "Error Indicator";
VAL_ 234 Type 0 "C-MDPS" 1 "R-MDPS(Dual Pinion)" 2 "R-MDPS(Belt)" 3 "SbW" 4 "RESERVED" 5 "RESERVED" 6 "RESERVED" 7 "Error Indicator";
VAL_ 234 EngineIdleRpmReq 0 "Current Consumption is Low" 1 "Current Consumption is High" 2 ":RESERVED" 3 "Error Indicator";
VAL_ 234 VSM_Stat 0 "The VSM function of MDPS is not plugged in (unplugged)." 1 "The VSM function of MDPS is plugged in." 2 "RESERVED" 3 "Error Indicator";
VAL_ 234 VSM_DefectiveStat 0 "MDPS is not defective" 1 "MDPS is defective" 2 "RESERVED" 3 "Error Indicator";
VAL_ 234 VSM_SignalStat 0 "VSM1 signal is not error" 1 "VSM signal is error" 2 "RESERVED" 3 "Error Indicator";
VAL_ 234 PA_Stat 0 "The PA function of MDPS is not plugged in (unplugged)." 1 "The PA function of MDPS is plugged in." 2 "RESERVED" 3 "Error Indicator";
VAL_ 234 PA_ModeStat 0 "RESERVED" 1 "Steering still in initialization phase" 2 "Steering ready, waits for PA command" 3 "Steering set in standby by PA" 4 "Steering requested to go to first activation step" 5 "Steering requested to go to final activation step" 6 "Steering went to error internally" 7 "Steering aborted the automatic function" 8 "RESERVED" 9 "RESERVED" 10 "RESERVED" 11 "RESERVED" 12 "RESERVED" 13 "RESERVED" 14 "RESERVED" 15 "Error Indicator";
VAL_ 234 PA_CanFailStat 0 "No Failure" 1 "Failure about Pa can message" 2 "RESERVED" 3 "Error Indicator";
VAL_ 234 LKA_Stat 0 "The LKA function of MDPS is not plugged in (unplugged)." 1 "The LKA function of MDPS is plugged in." 2 "RESERVED" 3 "Error Indicator";
VAL_ 234 LKA_ToiActiveStat 0 "Deactivated" 1 "Activated" 2 "RESERVED" 3 "Error Indicator";
VAL_ 234 LKA_ToiUnavailStat 0 "Available" 1 "Unavailable" 2 "RESERVED" 3 "Error Indicator";
VAL_ 234 LKA_ToiFaultStat 0 "No fault" 1 "Faulty" 2 "RESERVED" 3 "Error Indicator";
VAL_ 234 LKA_ToiFailStat 0 "Not in fail state" 1 "In fail state" 2 "RESERVED" 3 "Error Indicator";
VAL_ 234 ResetStat 0 "Normal" 1 "Reset Complete" 2 "Reset Fail" 3 "RESERVED";
VAL_ 234 SteerMode 0 "Comfort Mode" 1 "Sport Mode" 2 "Sport+ Mode" 3 "Chauffeur Mode" 4 "Mild Mode" 5 "Drift Mode" 6 "RESERVED" 7 "Error Indicator";
VAL_ 234 OutTorque 0 "0x0x000~0xFFD:real values" 4093 "0x0x000~0xFFD:real values" 4094 "RESERVED" 4095 "Error Indicator";
VAL_ 234 VSM_ActStat 0 "VSM Control inactivated" 1 "VSM Control Activated" 2 "RESERVED" 3 "Invalid";
VAL_ 234 ReprogramStat 0 "normal operation" 1 "reprogramming" 2 "RESERVED" 3 "Error Indicator";
VAL_ 234 SteerTorqueSensor 0 "0 (0x000~0x7FFD valid range)" 8189 "32765 (0x000~0x1FFD valid range)" 8190 "RESERVED" 8191 "Error Indicator";
VAL_ 234 PA_SteerAngle 0 "0 (0x000~0x7FFD valid range)" 32765 "32765 (0x000~0x7FFD valid range)" 32766 "Not Initialized" 32767 "Error Indicator" 32768 "32768 (0x8000~0xFFFF valid range)" 65535 "65535 (0x8000~0xFFFF valid range)";
VAL_ 234 LoamStat 0 "Normal" 1 "Loam Flag Warning Display" 2 "RESERVED" 3 "Error Indicator";
VAL_ 234 HDPSwVer 0 "HDP-MDPS Control Requirement Version" 1 "HDP-MDPS Control Requirement Version" 2 "HDP-MDPS Control Requirement Version" 3 "HDP-MDPS Control Requirement Version" 4 "HDP-MDPS Control Requirement Version" 5 "HDP-MDPS Control Requirement Version" 6 "HDP-MDPS Control Requirement Version" 7 "HDP-MDPS Control Requirement Version" 8 "HDP-MDPS Control Requirement Version" 9 "HDP-MDPS Control Requirement Version" 10 "HDP-MDPS Control Requirement Version" 11 "HDP-MDPS Control Requirement Version" 12 "HDP-MDPS Control Requirement Version" 13 "HDP-MDPS Control Requirement Version" 14 "HDP-MDPS Control Requirement Version" 15 "HDP-MDPS Control Requirement Version" 16 "HDP-MDPS Control Requirement Version" 17 "HDP-MDPS Control Requirement Version" 18 "HDP-MDPS Control Requirement Version" 19 "HDP-MDPS Control Requirement Version" 20 "HDP-MDPS Control Requirement Version" 21 "HDP-MDPS Control Requirement Version" 22 "HDP-MDPS Control Requirement Version" 23 "HDP-MDPS Control Requirement Version" 24 "HDP-MDPS Control Requirement Version" 25 "HDP-MDPS Control Requirement Version" 26 "HDP-MDPS Control Requirement Version" 27 "HDP-MDPS Control Requirement Version" 28 "HDP-MDPS Control Requirement Version" 29 "HDP-MDPS Control Requirement Version" 30 "HDP-MDPS Control Requirement Version" 31 "HDP-MDPS Control Requirement Version";
VAL_ 234 ADAS_ActiveStat 0 "INIT" 1 "INACTIVE" 2 "ACTIVE35(ACTIVE)" 3 "ACTIVE33(Redundancy)" 4 "RESERVED" 5 "RESERVED" 6 "RESERVED" 7 "RESERVED" 8 "RESERVED" 9 "RESERVED" 10 "RESERVED" 11 "RESERVED" 12 "RESERVED" 13 "RESERVED" 14 "RESERVED" 15 "RESERVED";
VAL_ 234 ADAS_AciPlugStat 0 "ADASAciNotPlugged-in" 1 "ADASAciPlugged-in" 2 "RESERVED" 3 "ErrorIndicator";
VAL_ 234 ADAS_AciFault 0 "No Fault" 1 "MDPS Fault" 2 "Fault Except MDPS" 3 "Both Fault";
VAL_ 234 EstSteerAngle 0 "0 (0x000~0x7FFD valid range)" 32765 "32765 (0x000~0x7FFD valid range)" 32766 "Not Initialized" 32767 "Error Indicator" 32768 "32768 (0x8000~0xFFFF valid range)" 65535 "65535 (0x8000~0xFFFF valid range)";
VAL_ 234 ADAS_ActiveStat_Lv2 0 "Not USED" 1 "INACTIVE" 2 "ACTIVE35(Active)" 3 "Reserved" 4 "Reserved" 5 "Reserved" 6 "Reserved" 7 "Reserved" 8 "Reserved" 9 "Reserved" 10 "Reserved" 11 "Reserved" 12 "Reserved" 13 "Reserved" 14 "Reserved" 15 "Reserved";
VAL_ 234 ADAS_AciFault_Lv2 0 "No Fault" 1 "MDPS Fault" 2 "Fault Except MDPS" 3 "Both Fault" 4 "Temporarily Unavailable" 5 "Temporarily Unavailable and MDPS Fault" 6 "Temporarily Unavailable and Fault Except MDPS" 7 "Temporarily Unavailable and Both Fault";
VAL_ 234 TPA_Stat 0 "The TPA function of MDPS is not plugged in (unplugged)" 1 "The TPA function of MDPS is plugged in" 2 "RESERVED" 3 "Error Indicator";
VAL_ 234 TPA_CanFailStat 0 "No Failure" 1 "Failure about Tpa can message" 2 "RESERVED" 3 "Error Indicator";
VAL_ 234 TPA_ModeStat 0 "RESERVED" 1 "Steering still in initialization phase" 2 "Steering ready, waits for TPA command" 3 "Steering set in standby by TPA" 4 "Steering requested to go to first activation step activation step" 5 "Steering requested to go to final activation step" 6 "Steering went to error internally" 7 "Steering aborted the automatic function" 14 "RESERVED" 15 "Error Indicator";
VAL_ 234 TPA_SteerAngle 0 "0 (0x000~0x7FFD valid range)" 32765 "32765 (0x000~0x7FFD valid range)" 32766 "Not Initialized" 32767 "Error Indicator" 32768 "32768 (0x8000~0xFFFF valid range)" 65535 "65535 (0x8000~0xFFFF valid range)";
VAL_ 234 LKA_FAULT 0 "ok" 1 "lka fault";
VAL_ 272 LKA_OptUsmSta 0 "None LKA/LDW Option (Default)" 1 "LDW" 2 "LKA" 3 "Reserved" 4 "LDW Only (None LKA)" 5 "LDW only OFF (None LKA)" 6 "LDW/LKA OFF" 7 "Invalid";
VAL_ 272 LKA_RcgSta 0 "Not Recognized" 1 "Left Lane Recognition" 2 "Right Lane Recognition" 3 "Full Lane Recognition" 4 "Reserved" 5 "Reserved" 6 "Reserved" 7 "Reserved";
VAL_ 272 LKA_LHLnWrnSta 0 "No Warning" 1 "Lane Departure Warning" 2 "Reserved" 3 "Reserved";
VAL_ 272 LKA_RHLnWrnSta 0 "No Warning" 1 "Lane Departure Warning" 2 "Reserved" 3 "Reserved";
VAL_ 272 LKA_HndsoffSnd 0 "Off" 1 "Hands-off Sound Warning" 2 "Reserved" 3 "Reserved";
VAL_ 272 LKA_StrSnd 0 "Off" 1 "Warning" 2 "Reserved" 3 "Reserved";
VAL_ 272 LKA_ICON 0 "Off" 1 "Unavailable_(Grey On)" 2 "Lane Recognized_(Green On)" 3 "Lane Departure_(Green Blink)" 4 "System Fail_(Orange On)" 5 "Not Calibrated_(Orange Blink)" 6 "Regulation_(Orange On)" 7 "Reserved";
VAL_ 272 StrTqReqVal 2046 "Reserved" 2047 "Invalid";
VAL_ 272 ActToiSta 0 "De-activate TOI" 1 "Activate TOI" 2 "Reserved" 3 "Error indicator";
VAL_ 272 ToiFltSta 0 "No Fault" 1 "Fault" 2 "Reserved" 3 "Error indicatorr";
VAL_ 272 LKA_SysWrn 0 "No Info" 1 "Reserved" 2 "Reserved" 3 "Reserved" 4 "Hands-Off Warning 1" 5 "Hands-Off Warning 2" 6 "Hands-Off Warning 3" 7 "Reserved" 8 "Reserved" 9 "System Automatic off" 10 "Reserved" 11 "Reserved" 12 "Reserved" 13 "Reserved" 14 "Reserved" 15 "System Fail";
VAL_ 272 LKA_UsmMod 0 "NONE" 1 "LKA 1 mode" 2 "Reserved" 3 "LDW";
VAL_ 272 ADAS_ACIAnglTqRedcGainVal 0 "0x0x00~0xFA:Real Values" 250 "0x0x00~0xFA:Real Values" 251 "RESERVED" 252 "RESERVED" 253 "RESERVED" 254 "RESERVED" 255 "RESERVED";
VAL_ 272 ADAS_AngleActiveStat_Lv2 0 "off" 1 "not active" 2 "active";
VAL_ 282 HBA_SysOptSta 0 "None HBA Option (Default)" 1 "HBA Option" 2 "Reserved" 3 "Error indicator";
VAL_ 282 HBA_SysSta 0 "HBA Disable" 1 "HBA Enable & High Beam Off" 2 "HBA Enable & High Beam On" 3 "Reserved" 4 "Reserved" 5 "Reserved" 6 "Reserved" 7 "System Fail";
VAL_ 282 HBA_IndLmpReq 0 "HBA Indicator Lamp Off" 1 "HBA Indicator Lamp On" 2 "Reserved" 3 "Error indicator";
VAL_ 282 FCA_Equip_MFC 0 "No Coding" 1 "Sensor Fusion FCA" 2 "Camera only FCA" 3 "No FCA Option" 4 "ADAS_DRV Option" 5 "Reserved" 6 "Not used" 7 "Error indicator";
VAL_ 282 HBA_OptUsmSta 0 "None HBA Option (Default)" 1 "HBA Function Off" 2 "HBA Function On" 3 "Invalid (Fail)";
VAL_ 282 DAW_LVDA_PUDis 0 "Default" 1 "Display “Leading vehicle departure alert”" 2 "Reserved" 3 "Error indicator";
VAL_ 282 DAW_LVDA_OptUsmSta 0 "No Option (default)" 1 "Off" 2 "On" 3 "Error Indicator";
VAL_ 282 DAW_OptUsmSta 0 "None DAW Option (Default)" 1 "System Off" 2 "System On" 3 "Reserved" 4 "Reserved" 5 "Reserved" 6 "Reserved" 7 "Invalid (Gray)";
VAL_ 282 DAW_SysSta 0 "System Off" 1 "Attention Level  1" 2 "Attention Level  2" 3 "Attention Level  3" 4 "Attention Level  4" 5 "Attention Level  5" 6 "Reserved" 7 "Reserved" 8 "Reserved" 9 "Reserved" 10 "Reserved" 11 "Reserved" 12 "Reserved" 13 "Reserved" 14 "System Standby" 15 "System Fail";
VAL_ 282 DAW_WrnMsgSta 0 "No Warning" 1 "Rest Recommend Warning" 2 "Hands-Off TMS call request" 3 "Reserved" 4 "Reserved" 5 "Reserved" 6 "Reserved" 7 "Error indicator";
VAL_ 282 DAW_TimeRstReq 0 "No signal" 1 "Time reset" 2 "Reserved" 3 "Error indicator";
VAL_ 282 DAW_SnstvtyModRetVal 0 "Default" 1 "Late" 2 "Normal" 3 "Reserved" 4 "Reserved" 5 "Reserved" 6 "Reserved" 7 "Invalid";
VAL_ 282 SCCEquipStat 0 "Not Applied" 1 "Applied" 2 "Not used" 3 "Error Indicator";
VAL_ 298 LKA_OptUsmSta 1 "warning only" 2 "assist" 6 "off";
VAL_ 298 LKA_ICON 0 "hidden" 1 "grey" 2 "green" 3 "flashing green";
VAL_ 298 LKA_OptUsmSta 0 "None LKA/LDW Option (Default)" 1 "LDW" 2 "LKA" 3 "Reserved" 4 "LDW Only (None LKA)" 5 "LDW only OFF (None LKA)" 6 "LDW/LKA OFF" 7 "Invalid";
VAL_ 298 LKA_RcgSta 0 "Not Recognized" 1 "Left Lane Recognition" 2 "Right Lane Recognition" 3 "Full Lane Recognition" 4 "Reserved" 5 "Reserved" 6 "Reserved" 7 "Reserved";
VAL_ 298 LKA_LHLnWrnSta 0 "No Warning" 1 "Lane Departure Warning" 2 "Reserved" 3 "Reserved";
VAL_ 298 LKA_RHLnWrnSta 0 "No Warning" 1 "Lane Departure Warning" 2 "Reserved" 3 "Reserved";
VAL_ 298 LKA_HndsoffSnd 0 "Off" 1 "Hands-off Sound Warning" 2 "Reserved" 3 "Reserved";
VAL_ 298 LKA_StrSnd 0 "Off" 1 "Warning" 2 "Reserved" 3 "Reserved";
VAL_ 298 LKA_ICON 0 "Off" 1 "Unavailable_(Grey On)" 2 "Lane Recognized_(Green On)" 3 "Lane Departure_(Green Blink)" 4 "System Fail_(Orange On)" 5 "Not Calibrated_(Orange Blink)" 6 "Regulation_(Orange On)" 7 "Reserved";
VAL_ 298 ADAS_StrTqReqVal 2046 "Reserved" 2047 "Invalid";
VAL_ 298 ADAS_ActToiSta 0 "De-activate TOI" 1 "Activate TOI" 2 "Reserved" 3 "Error indicator";
VAL_ 298 ADAS_ToiFltSta 0 "No Fault" 1 "Fault" 2 "Reserved" 3 "Error indicatorr";
VAL_ 298 LKA_SysWrn 0 "No Info" 1 "Reserved" 2 "Reserved" 3 "Reserved" 4 "Hands-Off Warning 1" 5 "Hands-Off Warning 2" 6 "Hands-Off Warning 3" 7 "Reserved" 8 "Reserved" 9 "System Automatic off" 10 "Reserved" 11 "Reserved" 12 "Reserved" 13 "Reserved" 14 "Reserved" 15 "System Fail";
VAL_ 298 FCA_LS_WrnSta 3 "ELK Steering to the right";
VAL_ 298 LKA_UsmMod 0 "NONE" 1 "LKA 1 mode" 2 "Reserved" 3 "LDW";
VAL_ 298 ELK_SymbDisp 3 "Evasive Action Taking Place";
VAL_ 304 PARK_BUTTON 1 "Pressed" 2 "Not Pressed";
VAL_ 304 PARK_BUTTON 1 "Pressed" 2 "Not Pressed";
VAL_ 304 KNOB_POSITION 1 "R" 2 "N (on R side)" 3 "Centered" 4 "N (on D side)" 5 "D";
VAL_ 304 GEAR 1 "P" 2 "R" 3 "N" 4 "D";
VAL_ 352 AEB_SETTING 1 "off" 2 "warning only" 3 "active assist";
VAL_ 353 FCA_ICON 0 "HIDDEN" 1 "ORANGE" 2 "RED";
VAL_ 353 FCA_ALT_ICON 0 "HIDDEN" 1 "ORANGE" 3 "RED";
VAL_ 353 HDA_ICON 0 "HIDDEN" 1 "GRAY" 2 "GREEN" 3 "WHITE" 5 "CYAN HDP";
VAL_ 353 SLA_ICON 0 "HIDDEN" 1 "WHITE UP" 2 "WHITE DOWN" 3 "GREEN UP" 4 "GREEN DOWN";
VAL_ 353 NAV_ICON 0 "HIDDEN" 1 "GRAY" 2 "GREEN" 4 "WHITE";
VAL_ 353 LFA_ICON 0 "HIDDEN" 1 "GRAY" 2 "GREEN" 3 "WHITE" 5 "CYAN";
VAL_ 353 DAW_ICON 0 "HIDDEN" 1 "ORANGE";
VAL_ 353 LKA_ICON 0 "HIDDEN" 1 "ORANGE" 3 "GRAY" 4 "GREEN";
VAL_ 353 HBA_ICON 0 "HIDDEN" 1 "GRAY" 2 "GREEN";
VAL_ 353 FCA_IMAGE 0 "HIDDEN" 2 "VISIBLE";
VAL_ 353 BCA_LEFT 0 "HIDDEN" 1 "VISIBLE" 2 "VISIBLE+ICON";
VAL_ 353 BCA_RIGHT 0 "HIDDEN" 1 "VISIBLE" 2 "VISIBLE+ICON";
VAL_ 353 CENTERLINE 0 "HIDDEN" 1 "GREEN";
VAL_ 353 TARGET 0 "HIDDEN" 1 "BLUE" 3 "WHITE";
VAL_ 353 LANE_LEFT 0 "HIDDEN" 1 "GREEN";
VAL_ 353 LANE_RIGHT 0 "HIDDEN" 1 "GREEN";
VAL_ 353 LANE_ZOOM 0 "ZOOM" 1 "HIDDEN";
VAL_ 353 LANELINE_LEFT 0 "GRAY" 1 "HIDDEN" 2 "WHITE" 4 "ORANGE" 6 "GREEN";
VAL_ 353 LANELINE_RIGHT 0 "GRAY" 1 "HIDDEN" 2 "WHITE" 4 "ORANGE" 6 "GREEN";
VAL_ 353 LANE_HIGHLIGHT 0 "HIDDEN" 1 "GREEN" 2 "WHITE" 3 "BLUE" 4 "ORANGE" 5 "RED";
VAL_ 353 LCA_LEFT_ARROW 0 "HIDDEN" 1 "VISIBLE";
VAL_ 353 LCA_RIGHT_ARROW 0 "HIDDEN" 1 "VISIBLE";
VAL_ 353 LCA_LEFT_ICON 0 "HIDDEN" 1 "GRAY" 2 "GREEN" 4 "WHITE";
VAL_ 353 LCA_RIGHT_ICON 0 "HIDDEN" 1 "GRAY" 2 "GREEN" 4 "WHITE";
VAL_ 353 ALERTS_1 0 "HIDDEN" 1 "WARNING_ONLY_CAR_CENTER" 2 "WARNING_ONLY_CAR_LEFT" 3 "WARNING_ONLY_CAR_RIGHT" 4 "WARNING_ONLY_LEFT" 5 "WARNING_ONLY_RIGHT" 11 "EMERGENCY_BRAKING_CAR_CENTER" 12 "EMERGENCY_BRAKING_CAR_LEFT" 13 "EMERGENCY_BRAKING_CAR_RIGHT" 14 "EMERGENCY_BRAKING_LEFT" 15 "EMERGENCY_BRAKING_RIGHT" 21 "EMERGENCY_STEERING_CAR_LEFT" 22 "EMERGENCY_STEERING_CAR_RIGHT" 23 "EMERGENCY_STEERING_CAR_LEFT_AWAY" 24 "EMERGENCY_STEERING_CAR_RIGHT_AWAY" 25 "EMERGENCY_STEERING_REAR_LEFT" 26 "EMERGENCY_STEERING_REAR_RIGHT" 33 "DRIVE_CAREFULLY";
VAL_ 353 ALERTS_2 0 "HIDDEN" 1 "KEEP_HANDS_ON_STEERING_WHEEL" 2 "KEEP_HANDS_ON_STEERING_WHEEL_RED" 3 "LANE_FOLLOWING_ASSIST_DEACTIVATED" 4 "HIGHWAY_DRIVING_ASSIST_DEACTIVATED" 5 "CONSIDER_TAKING_A_BREAK" 6 "PRESS_OK_BUTTON_TO_ENABLE_LANE_CHANGE_ASSIST" 7 "COLLISION_RISK_VEHICLE_TAKING_EMERGENCY_CONTROL" 8 "TAKE_CONTROL_OF_THE_VEHICLE_IMMEDIATELY_VEHICLE_IS_STOPPING" 9 "TAKE_CONTROL_OF_THE_VEHICLE_IMMEDIATELY" 11 "HIGHWAY_DRIVING_PILOT_SYSTEM_DEACTIVATED_AUDIBLE" 12 "KEEP_YOUR_EYES_ON_THE_ROAD" 13 "HIGHWAY_DRIVING_PILOT_CONDITIONS_NOT_MET_AUDIBLE" 14 "COLLISION_RISK_VEHICLE_TAKING_EMERGENCY_CONTROL" 15 "SET_THE_WIPER_AND_LIGHT_CONTROLS_TO_AUTO" 16 "BE_PREPARED_TO_TAKE_CONTROL_OF_THE_VEHICLE_AT_ANY_TIME" 21 "TAKE_CONTROL_OF_THE_VEHICLE_IMMEDIATELY_VEHICLE_IS_STOPPING" 10 "TAKE_CONTROL_OF_THE_VEHICLE_IMMEDIATELY";
VAL_ 353 ALERTS_3 0 "HIDDEN" 1 "AUTOMATICALLY_ADJUSTING_TO_THE_POSTED_SPEED_LIMIT" 2 "SET_SPEED_CHANGED" 3 "AUTOMATICALLY_ADJUSTING_TO_THE_POSTED_SPEED_LIMIT" 4 "SET_SPEED_CHANGED" 7 "DISTANCE_1" 8 "DISTANCE_2" 9 "DISTANCE_3" 10 "DISTANCE_4" 17 "DRIVE_CAREFULLY" 18 "CHECK_SURROUNDINGS" 19 "CONDITIONS_NOT_MET" 20 "LANES_NOT_DETECTED" 21 "CURVE_TOO_SHARP" 22 "LANE_TOO_NARROW" 23 "ROAD_TYPE_NOT_SUPPORTED" 24 "UNAVAILABLE_WITH_HAZARD_LIGHTS_ON" 25 "VEHICLE_SPEED_IS_TOO_LOW" 26 "KEEP_HANDS_ON_STEERING_WHEEL" 27 "LANE_TYPE_NOT_SUPPORTED" 28 "LANE_ASSIST_CANCELED_STEERING_INPUT_DETECTED";
VAL_ 353 ALERTS_4 0 "HIDDEN" 1 "TAKE_FOOT_OFF_THE_ACCELERATOR_PEDAL" 2 "TAKE_FOOT_OFF_THE_BRAKE_PEDAL" 3 "UNAVAILABLE_WHILE_HIGHWAY_DRIVING_PILOT_SYSTEM_IS_ACTIVE" 4 "TO_EXIT_HDP_GRASP_THE_STEERING_WHEEL_THEN_PRESS_AND_HOLD_THE_HDP_BUTTON" 5 "ACCELERATOR_PEDAL_OPERATION_LIMITED_FOR_SAFETY" 6 "TURN_OFF_HAZARD_WARNING_LIGHTS_AND_TURN_SIGNAL" 7 "KEEP_THE_DRIVERS_SEAT_IN_A_SAFE_DRIVING_POSITION" 16 "SET_SPEED_CHANGED" 17 "ACTIVATING_WINDSHIELD_DEFOG_TO_MAINTAIN_THE_DRIVERS_VIEW" 18 "SET_THE_WIPER_AND_LIGHT_CONTROLS_TO_AUTO" 19 "VEHICLE_SPEED_REDUCED_FOR_SAFETY_MERGING_LANES_AHEAD" 20 "SPEED_REDUCED_FOR_SAFETY_CONSTRUCTION_ZONE_DETECTED" 21 "VEHICLE_SPEED_LIMITED_SENSOR_DETECTION_RANGE_LIMITED" 22 "PREPARE_TO_TAKE_CONTROL_UNSUPPORTED_ROAD_TYPE_AHEAD" 23 "PREPARE_TO_TAKE_CONTROL_ENTRANCE_AND_EXIT_RAMPS_AHEAD" 24 "PREPARE_TO_TAKE_CONTROL_TOLLGATE_AHEAD" 25 "PREPARE_TO_TAKE_CONTROL_ROAD_EVENT_AHEAD" 26 "CLEARING_PATH_FOR_EMERGENCY_VEHICLE" 27 "VEHICLE_IS_TOO_SLOW_COMPARED_TO_TRAFFIC_FLOW" 28 "AFTER_SUNSET_HDP_IS_AVAILABLE_IN_AN_INSIDE_LANE_BEHIND_A_LEADING_VEHICLE" 29 "VEHICLE_SPEED_LIMITED_MERGING_LANES_AHEAD" 30 "VEHICLE_SPEED_LIMITED_CONSTRUCTION_ZONE_DETECTED" 31 "VEHICLE_SPEED_TEMPORARILY_LIMITED_FOR_SAFETY" 32 "PRESS_AND_HOLD_THE_BUTTON_TO_ACTIVATE_HIGHWAY_DRIVING_PILOT" 40 "HIGHWAY_DRIVING_PILOT_SYSTEM_IS_AVAILABLE" 64 "RESTART_VEHICLE_AFTER_EMERGENCY_STOP" 65 "CONNECTED_SERVICES_UNAVAILABLE" 66 "AVAILABLE_AFTER_VEHICLE_SOFTWARE_IS_UPDATED" 67 "ROAD_TYPE_NOT_SUPPORTED" 68 "ONLY_AVAILABLE_WHILE_DRIVING_ON_HIGHWAY_LANES" 69 "UNAVAILABLE_WHILE_OTHER_WARNINGS_ARE_ACTIVE" 70 "CANNOT_ACTIVATE_AT_ENTRANCE_EXIT_RAMPS" 71 "LANE_UNSUPPORTED" 72 "NOT_AVAILABLE_IN_THIS_COUNTRY" 79 "CHECKING_THE_DETECTION_RANGE_OF_THE_SENSOR" 80 "SHIFT_TO_D" 81 "ENGINE_STOPPED_BY_AUTO_STOP" 82 "INCREASE_DISTANCE_FROM_VEHICLE_AHEAD" 83 "VEHICLE_SPEED_IS_TOO_HIGH" 84 "CENTER_VEHICLE_IN_THE_LANE" 85 "PARKING_ASSIST_IS_ACTIVE" 86 "ESC_ACTIVIATION_REQUIRED" 87 "UNFOLD_SIDE_VIEW_MIRRORS" 88 "UNAVAILABLE_IN_THE_OUTER_LANE_AFTER_SUNSET" 89 "VEHICLE_SPEED_LIMITED_AFTER_SUNSET_FOR_SAFETY" 90 "LEADING_VEHICLE_NOT_DETECTED" 104 "AGGRESSIVE_BRAKING_OR_STEERING_DETECTED" 110 "SENSOR_AUTO_CALIBRATION_IN_PROGRESS_THIS_MAY_TAKE_SEVERAL_MINUTES" 111 "HIGHWAY_DRIVING_PILOT_WILL_BE_AVAILABLE_SHORTLY" 112 "IF_STEERING_WHEEL_IS_USED_HDP_WILL_BE_DEACTIVATED" 120 "IMPACT_DETECTED" 128 "UNSUITABLE_USE_OF_ACCELERATOR_PEDAL_DETECTED" 129 "GEAR_SHIFTER_USE_DETECTED" 130 "UNSUITABLE_BRAKE_PEDAL_USE_DETECTED" 131 "VEHICLE_START_BUTTON_PRESSED" 132 "VEHICLE_HAS_BEEN_STOPPED_FOR_TOO_LONG" 141 "TRAFFIC_CONGESTION_HAS_CLEARED" 142 "ENTRANCE_AND_EXIT_RAMPS_AHEAD" 143 "UNSUPPORTED_LANE_AHEAD" 144 "UNSUPPORTED_ROAD_TYPE_AHEAD" 145 "LANE_DEPARTURE_DETECTED" 146 "MAXIMUM_SPEED_EXCEEDED" 147 "HIGHWAY_DRIVING_PILOT_LIMITED_ABNORMAL_VEHICLE_CONTROLLER_STATUS" 148 "WIPER_LIGHT_CONTROL_SETTINGS_ARE_UNSUITABLE_FOR_USE_WITH_HDP" 149 "WINDSHIELD_DEFOG_SYSTEM_STATUS_IS_UNSUITABLE_FOR_USE_WITH_HDP" 150 "HAZARD_WARNING_LIGHTS_OR_TURN_SIGNAL_OPERATION_DETECTED" 151 "PERFORMING_EVASIVE_STEERING_OBSTACLES_DETECTED_AHEAD" 152 "HIGHWAY_DRIVING_PILOT_LIMITED_SENSOR_DETECTION_RANGE_LIMITED" 160 "CHECK_HIGHWAY_DRIVING_PILOT_SYSTEM" 161 "SAFETY_FUNCTION_ACTIVATED" 176 "CAMERA_OBSCURED" 177 "RADAR_BLOCKED" 178 "LIDAR_BLOCKED" 179 "AIRBAG_WARNING_LIGHT_IS_ON" 180 "ATTACHED_TRAILED_DETECTED" 181 "HIGH_OUTSIDE_TEMPERATURE" 182 "LOW_OUTSIDE_TEMPERATURE" 190 "UNAVAILABLE_DUE_TO_THE_ROAD_EVENT_INFORMATION_RECEIVED" 191 "UNAVAILABLE_NEAR_TOLLGATES" 192 "DRIVERS_SEAT_IS_NOT_IN_A_SAFE_DRIVING_POSITION" 193 "VEHICLE_DRIVING_THE_WRONG_WAY_DETECTED_AHEAD" 194 "EMERGENCY_VEHICLE_DETECTED" 195 "OBSTACLE_DETECTED_AHEAD" 196 "SENSOR_BLOCKED_DUE_TO_RAIN_SNOW_OR_ROAD_DEBRIS" 197 "SLIPPERY_ROAD_SURFACE_DETECTED" 198 "CONSTRUCTION_ZONE_DETECTED_AHEAD" 199 "PEDESTRIAN_DETECTED_AHEAD" 200 "UNSUITABLE_DRIVERS_SEAT_POSITION_DETECTED" 201 "FOLDED_SIDE_VIEW_MIRRORS_DETECTED" 208 "VEHICLE_POSITION_NOT_DETECTED" 209 "LANE_NOT_DETECTED" 210 "DRIVER_NOT_DETECTED" 211 "KEEP_YOUR_EYES_ON_THE_ROAD" 212 "LEADING_VEHICLE_REQUIRED_AFTER_SUNSET" 213 "TBD" 240 "LOW_FUEL" 241 "LOW_TIRE_PRESSURE" 242 "DOOR_OPEN" 243 "TRUNK_OPEN" 244 "HOOD_OPEN" 245 "SEAT_BELT_NOT_FASTENED" 246 "PARKING_BRAKE_ACTIVATED" 247 "LOW_EV_BATTERY" 248 "HDP_DEACTIVATION_DELAYED_RISK_OF_COLLISION_DETECTED" 249 "LIFTGATE_OPENED";
VAL_ 353 ALERTS_5 0 "HIDDEN" 1 "DRIVERS_GRASP_NOT_DETECTED_DRIVING_SPEED_WILL_BE_LIMITED" 2 "WATCH_FOR_SURROUNDING_VEHICLES" 3 "SMART_CRUISE_CONTROL_DEACTIVATED" 4 "SMART_CRUISE_CONTROL_CONDITIONS_NOT_MET" 5 "USE_SWITCH_OR_PEDAL_TO_ACCELERATE" 6 "DRIVER_ASSISTNCE_SYSTEM_LIMITED_TRAILER_ATTACHED" 7 "DRIVER_ASSISTNCE_SYSTEM_LIMITED_DRIVER_FULL_FACE_NOT_VISIBLE" 11 "LEADING_VEHICLE_IS_DRIVING_AWAY" 12 "STOP_VEHICLE_THEN_TRY_AGAIN" 19 "ACTIVATING_HIGHWAY_DRIVING_PILOT_SYSTEM" 20 "CONTINUING_USE_OF_HIGHWAY_DRIVING_PILOT_WILL_RESULT_IN_DEVIATION_FROM_THE_NAVIGATION_ROUTE" 21 "HIGHWAY_DRIVING_PILOT_SYSTEM_DEACTIVATED_SILENT" 22 "HIGHWAY_DRIVING_PILOT_SYSTEM_NOT_APPLIED" 23 "HIGHWAY_DRIVING_PILOT_CONDITIONS_NOT_MET_SILENT";
VAL_ 353 MUTE 0 "NONE" 1 "MUTED";
VAL_ 353 SOUNDS_1 0 "NONE" 3 "FAST BEEP" 6 "CONSTANT BEEP";
VAL_ 353 SOUNDS_2 0 "NONE" 2 "SINGLE CHIME" 3 "CONSTANT CHIME" 6 "FAST BEEP";
VAL_ 353 SOUNDS_3 0 "NONE" 3 "SOFT CHIME" 5 "SINGLE CHIME";
VAL_ 353 SOUNDS_4 0 "NONE" 2 "DOUBLE CHIME";
VAL_ 353 SETSPEED_HUD 0 "HIDDEN" 1 "GRAY" 2 "GREEN" 3 "WHITE" 5 "CYAN";
VAL_ 353 DISTANCE_LEAD 0 "HIDDEN" 1 "GRAY" 2 "WHITE";
VAL_ 353 DISTANCE_CAR 0 "HIDDEN" 1 "GRAY" 2 "WHITE" 3 "CYAN A";
VAL_ 353 DISTANCE_SPACING 0 "HIDDEN" 1 "BLUE" 3 "WHITE" 5 "CYAN";
VAL_ 353 SETSPEED 0 "HIDDEN" 1 "GRAY" 2 "GREEN" 3 "WHITE" 6 "CYAN";
VAL_ 353 HDA_ICON 0 "HIDDEN" 1 "GRAY" 2 "GREEN" 3 "WHITE" 5 "CYAN HDP";
VAL_ 353 SLA_ICON 0 "HIDDEN" 1 "WHITE UP" 2 "WHITE DOWN" 3 "GREEN UP" 4 "GREEN DOWN";
VAL_ 353 NAV_ICON 0 "HIDDEN" 1 "GRAY" 2 "GREEN" 4 "WHITE";
VAL_ 353 LFA_ICON 0 "HIDDEN" 1 "GRAY" 2 "GREEN" 3 "WHITE" 5 "CYAN";
VAL_ 353 LCA_LEFT_ICON 0 "HIDDEN" 1 "GRAY" 2 "GREEN" 4 "WHITE";
VAL_ 353 LCA_RIGHT_ICON 0 "HIDDEN" 1 "GRAY" 2 "GREEN" 4 "WHITE";
VAL_ 353 BACKGROUND 0 "HIDDEN" 1 "BLUE" 3 "ORANGE" 4 "FLASHING ORANGE" 6 "FLASHING RED" 7 "GRAY";
VAL_ 353 DAW_ICON 0 "HIDDEN" 1 "ORANGE";
VAL_ 353 CAR_CIRCLE 0 "HIDDEN" 1 "GRAY" 2 "CYAN";
VAL_ 354 COUNTRY 0 "HIDDEN" 1 "KOREA" 4 "INTL" 5 "JAPAN" 6 "CANADA" 7 "USA" 8 "CHINA" 9 "INTL";
VAL_ 354 SPEEDLIMIT_FLASH 0 "HIDDEN" 1 "ERROR" 2 "NORMAL" 4 "RED";
VAL_ 354 ROAD_SIGNS 0 "HIDDEN" 1 "SCHOOL_ZONE" 2 "PEDESTRIAN_CROSSING" 8 "STOP" 9 "YIELD" 16 "DO_NOT_PASS" 19 "DO_NOT_ENTER" 24 "ROUNDABOUT" 26 "RIGHT_CURVE_AHEAD" 27 "LEFT_CURVE_AHEAD" 28 "SLIGHT_RIGHT_CURVE_AHEAD" 29 "SLIGHT_LEFT_CURVE_AHEAD";
VAL_ 354 SPEEDLIMIT_WEATHER 0 "HIDDEN" 1 "RAIN" 2 "SNOW" 3 "RAIN+SNOW" 4 "TRAILER";
VAL_ 354 VIBRATE 0 "NONE" 1 "VIBRATE";
VAL_ 354 FF_DETECT 0 "HIDDEN" 1 "GRAY BOX" 2 "WHITE BOX" 3 "GRAY CAR" 4 "WHITE CAR" 5 "GRAY TRUCK" 6 "WHITE TRUCK" 7 "GRAY PERSON" 8 "WHITE PERSON" 9 "GRAY BICYCLE" 10 "WHITE BICYCLE" 11 "GRAY MOTORCYCLE" 12 "WHITE MOTORCYCLE" 13 "DARK CONE" 14 "ORANGE CONE";
VAL_ 354 FF_DETECT_ALT 0 "HIDDEN" 1 "GRAY BOX" 2 "WHITE BOX" 3 "DIM CONE" 4 "ORANGE CONE";
VAL_ 354 LF_DETECT 0 "HIDDEN" 1 "GRAY BOX" 2 "WHITE BOX" 3 "GRAY CAR" 4 "WHITE CAR" 5 "GRAY TRUCK" 6 "WHITE TRUCK" 7 "GRAY PERSON" 8 "WHITE PERSON" 9 "GRAY BICYCLE" 10 "WHITE BICYCLE" 11 "GRAY MOTORCYCLE" 12 "WHITE MOTORCYCLE" 13 "DARK CONE" 14 "ORANGE CONE";
VAL_ 354 LR_DETECT 0 "HIDDEN" 1 "GRAY BOX" 2 "WHITE BOX" 3 "GRAY CAR" 4 "WHITE CAR" 5 "GRAY TRUCK" 6 "WHITE TRUCK" 7 "GRAY PERSON" 8 "WHITE PERSON" 9 "GRAY BICYCLE" 10 "WHITE BICYCLE" 11 "GRAY MOTORCYCLE" 12 "WHITE MOTORCYCLE" 13 "DARK CONE" 14 "ORANGE CONE";
VAL_ 354 RF_DETECT 0 "HIDDEN" 1 "GRAY BOX" 2 "WHITE BOX" 3 "GRAY CAR" 4 "WHITE CAR" 5 "GRAY TRUCK" 6 "WHITE TRUCK" 7 "GRAY PERSON" 8 "WHITE PERSON" 9 "GRAY BICYCLE" 10 "WHITE BICYCLE" 11 "GRAY MOTORCYCLE" 12 "WHITE MOTORCYCLE" 13 "DARK CONE" 14 "ORANGE CONE";
VAL_ 354 RR_DETECT 0 "HIDDEN" 1 "GRAY BOX" 2 "WHITE BOX" 3 "GRAY CAR" 4 "WHITE CAR" 5 "GRAY TRUCK" 6 "WHITE TRUCK" 7 "GRAY PERSON" 8 "WHITE PERSON" 9 "GRAY BICYCLE" 10 "WHITE BICYCLE" 11 "GRAY MOTORCYCLE" 12 "WHITE MOTORCYCLE" 13 "DARK CONE" 14 "ORANGE CONE";
VAL_ 354 FAULT_FSS 0 "HIDDEN" 1 "CHECK_FORWARD_SAFETY_SYSTEM" 2 "FORWARD_SAFETY_SYSTEM_LIMITED_CAMERA_OBSCURED" 3 "FORWARD_SAFETY_SYSTEM_LIMITED_RADAR_BLOCKED";
VAL_ 354 FAULT_FCA 0 "HIDDEN" 1 "CHECK_FORWARD_SIDE_SAFETY_SYSTEM" 2 "FORWARD_SIDE_SAFETY_SYSTEM_LIMITED_CAMERA_OBSCURED" 3 "FORWARD_SIDE_SAFETY_SYSTEM_LIMITED_RADAR_BLOCKED";
VAL_ 354 FAULT_LSS 0 "HIDDEN" 1 "CHECK_LANE_SAFETY_SYSTEM" 2 "LANE_SAFETY_SYSTEM_DISABLED_CAMERA_OBSCURED";
VAL_ 354 FAULT_SLA 0 "HIDDEN" 1 "CHECK_SPEED_LIMIT_SYSTEM" 2 "SPEED_LIMIT_SYSTEM_DISABLED_CAMERA_OBSCURED";
VAL_ 354 FAULT_DAW 0 "HIDDEN" 1 "CHECK_INATTENTIVE_DRIVING_WARNING_SYSTEM" 2 "INATTENTIVE_DRIVING_WARNING_SYSTEM_DISABLED_CAMERA_OBSCURED";
VAL_ 354 FAULT_HBA 0 "HIDDEN" 1 "CHECK_HIGH_BEAM_ASSIST_SYSTEM";
VAL_ 354 FAULT_SCC 0 "HIDDEN" 1 "CHECK_SMART_CRUISE_CONTROL_SYSTEM" 2 "SMART_CRUISE_CONTROL_DISABLED_RADAR_BLOCKED";
VAL_ 354 FAULT_LFA 0 "HIDDEN" 1 "CHECK_LANE_FOLLOWING_SYSTEM_ASSIST_SYSTEM";
VAL_ 354 FAULT_HDA 0 "HIDDEN" 1 "CHECK_HIGHWAY_DRIVING_ASSIST_SYSTEM";
VAL_ 354 FAULT_LCA 0 "HIDDEN" 1 "CHECK_LANE_CHANGE_ASSIST_FUNCTION" 2 "LANE_CHANGE_ASSIST_FUNCTION_DISABLED_CAMERA_OBSCURED" 3 "LANE_CHANGE_ASSIST_FUNCTION_DISABLED_RADAR_BLOCKED";
VAL_ 354 FAULT_HDP 0 "HIDDEN" 1 "CHECK_HIGHWAY_DRIVING_PILOT_SYSTEM" 2 "HIGHWAY_DRIVING_PILOT_DISABLED_CAMERA_OBSCURED" 3 "HIGHWAY_DRIVING_PILOT_DISABLED_RADAR_BLOCKED" 4 "HIGHWAY_DRIVING_PILOT_DISABLED_LIDAR_BLOCKED";
VAL_ 354 FAULT_DAS 0 "HIDDEN" 1 "CHECK_DRIVER_ASSISTANCE_SYSTEM" 2 "DRIVER_ASSISTANCE_SYSTEM_LIMITED_CAMERA_OBSCURED" 3 "DRIVER_ASSISTANCE_SYSTEM_LIMITED_RADAR_BLOCKED" 4 "DRIVER_ASSISTANCE_SYSTEM_LIMITED_CAMERA_OBSCURED_AND_RADAR_BLOCKED";
VAL_ 354 FAULT_ESS 0 "HIDDEN" 1 "CHECK_EMERGENCY_STOPPING_FUNCTION" 2 "EMERGENCY_STOPPING_FUNCTION_DISABLED_CAMERA_OBSCURED" 3 "EMERGENCY_STOPPING_FUNCTION_DISABLED_RADAR_BLOCKED";
VAL_ 362 BLINKER_CONTROL 1 "hazards" 2 "hazards button backlight" 3 "left blinkers" 4 "right blinkers";
VAL_ 373 ACCEnable 0 "SCC ready" 1 "SCC temp fault" 2 "SCC permanent fault" 3 "SCC permanent fault, communication issue";
VAL_ 373 SCC_OptTyp 0 "SCC is not equipped" 1 "SCC is equipped" 2 "Not used" 3 "Error Indicator";
VAL_ 373 SCC_ReqLimSta 0 "No request" 1 "Limited No Limitation" 2 "Acceleration Limited" 3 "Deceleration Limited";
VAL_ 373 ESC_StdStillVal 0 "No stand still detected" 1 "stand still detected" 2 "Not used" 3 "Error Indicator";
VAL_ 373 ESC_DclEnblReq 0 "Disable deceleration control" 1 "Enable deceleration control" 2 "Not used" 3 "Error Indicator";
VAL_ 373 ESC_PrkBrkActvSta 0 "Parking brake is not activated" 1 "Parking brake is activated" 2 "Not used" 3 "Error Indicator";
VAL_ 373 FCA_EquipSta 0 "FCA is not equipped" 1 "FCA is equipped" 2 "Not used" 3 "Error Indicator";
VAL_ 373 FCA_AvlblSta 0 "Available" 1 "Temporarily not available" 2 "Permanently not available" 3 "FCA Communication Error";
VAL_ 416 ACCMode 0 "off" 1 "enabled" 2 "driver_override" 3 "off_maybe_fault" 4 "cancelled";
VAL_ 416 ObjectDistance 2046 "Default" 2047 "Error";
VAL_ 416 ObjectRelativeSpeed 4094 "Default" 4095 "Error";
VAL_ 416 ObjectLateralPosition 510 "Default" 511 "Error";
VAL_ 416 SysFailStat 0 "System without error" 1 "Performance degredation" 2 "System temporairy unavailable" 3 "SCC Service Required";
VAL_ 416 MainStat 0 "OFF" 1 "ON" 2 "Not used" 3 "Error Indicator";
VAL_ 416 OperationStat 0 "Off" 1 "Engaged" 2 "Override" 3 "Shutoff" 4 "Canceled or Paused";
VAL_ 416 TakeoverReq 0 "No takeover request" 1 "Takeover request" 2 "Not used" 3 "Error Indicator";
VAL_ 416 InfoDisplay 0 "-" 1 "Display “SCC Mode”" 2 "Display “Conventional Cruise Mode”" 3 "Display “Object disappeared at low speed”" 4 "Display “Available to resume acceleration control”" 7 "Invalid";
VAL_ 416 AlertDisplay 0 "-" 1 "Display 'SCC Disengaged'" 2 "Display 'No SCC Engage Condition!'" 3 "Display 'SCC Disengaged When The Vehicle Stops'";
VAL_ 416 ObjectDistanceLevel 0 "No in-path object detected" 1 "Distance Warning" 2 "1st Object Distance Level" 3 "2nd Object Distance Level" 4 "3rd Object Distance Level" 5 "4th Object Distance Level" 255 "Error Indicator";
VAL_ 416 DistanceGapSet 0 "No time gap set" 1 "1st level distance" 2 "2nd level distance" 3 "3rd level distance" 4 "4th level distance" 14 "SCC-ML Active" 15 "Error Indicator";
VAL_ 416 NSCC_AutoSetStat 0 "Auto Set Speed Off" 1 "Auto Set Speed On" 3 "Error Indicator";
VAL_ 416 VSetDis 255 "Error";
VAL_ 416 NSCC_OperationStat 0 "Off" 1 "Ready" 2 "Act" 3 "Error Indicator";
VAL_ 416 NSCC_MainStat 0 "Default" 1 "Off" 2 "On" 3 "Invalid";
VAL_ 416 ObjectStat 0 "No in-path object detected" 1 "In-path object detected (uncontrollable)" 2 "In-path object detected (controllable:longitudinal)";
VAL_ 416 SensitiveMode 0 "Default" 1 "Comford Mode" 2 "Normal Mode" 3 "Dynamic Mode" 7 "Invalid";
VAL_ 416 NSCC_AutoSetSpeedStat 0 "Auto Set Speed Update Off" 1 "Auto Set Speed Update On" 3 "Error Indicator";
VAL_ 416 NSCC_InfoDisplay 0 "None" 1 "NSCC Warning";
VAL_ 416 AccelRequest 2047 "Error";
VAL_ 416 AccelRequestRaw 2047 "Error";
VAL_ 416 JerkUpperLimit 127 "No Limit";
VAL_ 416 JerkLowerLimit 127 "No Limit";
VAL_ 416 AccelLimitBandUpper 0 "Precise Control";
VAL_ 416 AccelLimitBandLower 0 "Precise Control";
VAL_ 416 StopReq 0 "No request" 1 "Stop control is required" 2 "Not used" 3 "Error Indicator";
VAL_ 416 EngineStopReq 0 "SCC deactive or SCC off" 1 "'ISG Stop' Possible" 2 "'ISG Start or Maintain Engine Run' Request";
VAL_ 416 TargetDistance 2046 "Default" 2047 "Error";
VAL_ 426 CRUISE_BUTTONS 0 "none" 1 "res_accel" 2 "set_decel" 3 "gap_distance" 4 "pause_resume";
VAL_ 437 LeftLnQualStat 0 "Very Low Quality" 1 "Low Quality" 2 "High Quality" 3 "Very High Quality" 4 "Reserved" 5 "Reserved" 6 "Reserved" 7 "Error indicator";
VAL_ 437 LeftLnDptStat 0 "No Left Line Departure" 1 "Left Line Departure" 2 "Reserved" 3 "Error Indicator";
VAL_ 437 RightLnQualStat 0 "Very Low Quality" 1 "Low Quality" 2 "High Quality" 3 "Very High Quality" 4 "Reserved" 5 "Reserved" 6 "Reserved" 7 "Error indicator";
VAL_ 437 RightLnDptStat 0 "No Right Line Departure" 1 "Right Line Departure" 2 "Reserved" 3 "Error Indicator";
VAL_ 437 RightLnCurvature 65534 "Reserved" 65535 "Error indicator";
VAL_ 442 BCW_LeftIndSta 0 "No detection" 1 "Blind-spot warning active" 2 "Blind-spot warning + blinker, flashing" 3 "Reserved";
VAL_ 442 BCW_RightIndSta 0 "No detection" 1 "Blind-spot warning active" 2 "Blind-spot warning + blinker, flashing" 3 "Reserved";
VAL_ 463 CRUISE_BUTTONS 0 "none" 1 "res_accel" 2 "set_decel" 3 "gap_distance" 4 "pause_resume";
VAL_ 463 RIGHT_PADDLE 0 "Not Pulled" 1 "Pulled";
VAL_ 463 LEFT_PADDLE 0 "Not Pulled" 1 "Pulled";
VAL_ 480 HDA_OptUsmSta 0 "Not Applied" 1 "Function Off" 2 "Function On" 3 "Reserved" 4 "Reserved" 5 "Reserved" 6 "Reserved" 7 "Invalid (Fail)" ;
VAL_ 480 LFA_OptUsmSta 0 "Not Applied" 1 "Function Off" 2 "Function On" 3 "Reserved" 4 "Reserved" 5 "Reserved" 6 "Reserved" 7 "Invalid (Fail)" ;
VAL_ 480 HDA_CntrlModSta 0 "System Deactive (Default)" 1 "System Ready" 2 "System Active" 3 "Reserved" ;
VAL_ 480 HDA_InfoPUDis 0 "No pop-up" 1 "system start pop-up" 2 "system auto disengaged pop-up by highway off" 3 "system auto disengaged pop-up" 4 "system Fail pop-up" 5 "Hands-off pop up" 6 "Hands-off pop up w/ sound" 7 "System Automatic off" ;
VAL_ 480 HDA_AutoSetSpdSta 0 "Auto Set Speed Off" 1 "Auto Set Speed On" 2 "Reserved" 3 "Error indicator" ;
VAL_ 480 HDA_AutoSetSpdUpdtSta 0 "Auto Set Speed Update Off" 1 "Auto Set Speed Update On" 2 "Reserved" 3 "Error indicator" ;
VAL_ 480 HDA_LFA_SymSta 0 "Off" 1 "Gray" 2 "Green" 3 "Green blink" ;
VAL_ 480 HDA_LFA_WrnSnd 0 "Off " 1 "Additional Warning Sound" 2 "Reserved" 3 "Error indicator" ;
VAL_ 480 HDA_InfoPUDis1 0 "No Pop-up" 1 "System Automatic off (LFA)" 2 "System Automatic off (HDA)" 3 "Reserved" 4 "Reserved" 5 "Reserved" 6 "Not Used" 7 "Error Indicator" ;
VAL_ 480 HDA_TDMRMDclReq 0 "Not automatically deactivated state of LFA (default)" 1 "Automatically deactivated state of LFA" 2 "Reserved" 3 "Reserved" ;
VAL_ 490 HDA_MODE2 1 "Lane change icon gray" 2 "lane green + lane change icon green" 3 "lane green + lane change icon green (both blinking)" 4 "lane white + lane change icon white (both blinking rapidly)" 5 "Lane Change Assist system check warning";
VAL_ 490 LANE_LEFT 0 "IDLE" 1 "ON_SOURCE" 2 "ON_TARGET";
VAL_ 490 LANE_RIGHT 0 "IDLE" 1 "ON_SOURCE" 2 "ON_TARGET";
VAL_ 490 LANE_CHANGING 0 "IDLE" 1 "LEFT_CHECK" 3 "LEFT_CHANGING" 2 "RIGHT_CHECK" 4 "RIGHT_CHANGING";
VAL_ 490 LF_DETECT 0 "none" 1 "gray" 2 "white" 3 "white" 4 "hide";
VAL_ 490 RF_DETECT 0 "none" 1 "gray" 2 "white" 3 "white" 4 "hide";
VAL_ 490 LR_DETECT 0 "none" 1 "gray" 2 "white" 3 "white" 4 "hide";
VAL_ 490 RR_DETECT 0 "none" 1 "gray" 2 "white" 3 "white" 4 "hide";
VAL_ 490 AUTOLANECHANGE_MSG 1 "Check surrounding conditions" 2 "Operating conditions not met" 3 "Analyzing driving lane" 4 "Sharp curve ahead" 5 "Current lane is too narrow" 6 "Not an operational section" 7 "Hazard lights are on" 8 "Vehicle speed is too low" 9 "Please hold the steering wheel" 10 "Not an operable lane" 11 "Steering input detected" 12 "Press the OK button to activate lane change assist";
VAL_ 490 LANELINE_CURVATURE_DIRECTION 0 "LEFT" 1 "RIGHT";
VAL_ 506 ISLW_OptUsmSta 0 "None ISLW Option" 1 "System Disabled by USM" 2 "System Enable by USM" 3 "Invalid";
VAL_ 506 SysSta 0 "Normal (Default)" 1 "System Fail" 2 "ISLW Temporary Unavailable" 3 "Reserved";
VAL_ 506 NoPassingInfoDis 0 "None Display" 1 "LHD No Passing Zone Display" 2 "RHD No Passing Zone Display" 3 "Reserved" 4 "Reserved" 5 "Reserved" 6 "Reserved" 7 "Invalid";
VAL_ 506 OvrlpSignDis 0 "None" 1 "Overlap Sign" 2 "Reserved" 3 "Error indicator";
VAL_ 506 CluSpeedLimit 0 "No Recognition" 253 "Unlimited Speed" 254 "Reserved" 255 "Invalid";
VAL_ 506 NavSpeedLimit 0 "No Recognition" 253 "Unlimited Speed" 254 "Reserved" 255 "Invalid";
VAL_ 506 SubCondinfoSta1 0 "None" 1 "Rain" 2 "Snow" 3 "Snow&Rain" 4 "Trailer" 5 "Reserved" 6 "Reserved" 7 "Reserved" 8 "Reserved" 9 "Reserved" 10 "Reserved" 11 "Reserved" 12 "Reserved" 13 "Reserved" 14 "Generic" 15 "Invalid";
VAL_ 506 SubCondinfoSta2 0 "None" 1 "Rain" 2 "Snow" 3 "Snow&Rain" 4 "Trailer" 5 "Reserved" 6 "Reserved" 7 "Reserved" 8 "Reserved" 9 "Reserved" 10 "Reserved" 11 "Reserved" 12 "Reserved" 13 "Reserved" 14 "Generic" 15 "Invalid";
VAL_ 506 SpdCluSubMainDis 0 "No Recognition" 253 "Unlimited Speed" 254 "Reserved" 255 "Invalid";
VAL_ 506 SpdCluDisSubCond1 0 "No Recognition" 253 "LHD Conditional No Passing ZONE" 254 "RHD Conditional No Passing ZONE" 255 "Invalid";
VAL_ 506 SpdCluDisSubCond2 0 "No Recognition" 253 "LHD Conditional No Passing ZONE" 254 "RHD Conditional No Passing ZONE" 255 "Invalid";
VAL_ 506 SpdNaviSubMainDis 0 "No Recognition" 253 "Unlimited Speed" 254 "Reserved" 255 "Invalid";
VAL_ 506 SpdNaviDisSubCond1 0 "No Recognition" 253 "LHD Conditional No Passing ZONE" 254 "RHD Conditional No Passing ZONE" 255 "Invalid";
VAL_ 506 SpdNaviDisSubCond2 0 "No Recognition" 253 "LHD Conditional No Passing ZONE" 254 "RHD Conditional No Passing ZONE" 255 "Invalid";
VAL_ 506 SpdwOffst 0 "No Recognition" 253 "Unlimited Speed" 254 "Reserved" 255 "Invalid";
VAL_ 506 SwIgnoreReq 0 "Allow All Switch Inputs" 1 "-(SET) Switch Input Ignore" 2 "+(SET) Switch Input Ignore" 3 "-(SET) & +(SET) Switch Inputs Ignore";
VAL_ 506 SpdChgReq 0 "Default" 1 "Speed Change Request" 2 "Reserved" 3 "Reserved";
VAL_ 506 SpdWrn 0 "No Warning" 1 "Warning" 2 "Reserved" 3 "Reserved";
VAL_ 506 IcyWrn 0 "No Warning" 1 "Warning" 2 "Reserved" 3 "Reserved";
VAL_ 506 SymFlashMod 0 "No Flasing" 1 "Flashing Sign" 2 "Flashing - Arrow Symbol" 3 "Flashing + Arrow Symbol" 4 "Flashing Auto Symbol" 5 "Reserved" 6 "Reserved" 7 "Reserved";
VAL_ 506 Popup 0 "No Popup" 1 "MSLA Speed will Change" 2 "MSLA Speed has Changed" 3 "CC_SCC Speed will Change" 4 "CC_SCC Speed has Changed" 5 "Reserved" 6 "Reserved" 7 "Reserved";
VAL_ 506 ISLA_OptUsmSta 0 "None ISLA Option" 1 "Off" 2 "Warning" 3 "Assist" 4 "Reserved" 5 "Reserved" 6 "Reserved" 7 "Invalid (GRAY)";
VAL_ 506 OffstUsmSta 0 "None Offset Function" 1 "-10kph or -5mph" 2 "-5kph or -3mph" 3 "0kph or 0mph" 4 "+5kph or +3mph" 5 "+10kph or +5mph" 6 "Reserved" 7 "Invalid (GRAY)";
VAL_ 506 AutoUsmSta 0 "None Auto Function" 1 "Auto Off" 2 "Auto On" 3 "Invalid (GRAY)";
VAL_ 506 Country 0 "Europe" 1 "Korea" 2 "China" 3 "USA" 4 "Canada" 5 "Australia" 6 "Reserved" 7 "Reserved" 8 "Reserved" 9 "Reserved" 10 "Reserved" 11 "Reserved" 12 "Reserved" 13 "Reserved" 14 "Reserved" 15 "Initial Value";
VAL_ 506 ROAD_SIGNS 0 "No Recognition" 1 "School Zone" 2 "Pedestrian Crossing" 3 "Bicycle Crossing" 4 "Reserved" 5 "Reserved" 6 "Reserved" 7 "Reserved" 8 "Stop" 9 "Yield" 10 "Stop Ahead" 11 "Yield Ahead" 12 "Road Construction Ahead" 13 "Lane Reduction" 14 "Reserved" 15 "Reserved" 16 "Do Not Pass" 17 "Reserved" 18 "Reserved" 19 "Reserved" 20 "Reserved" 21 "Reserved" 22 "Reserved" 23 "Reserved" 24 "Exit" 25 "Roundabout" 26 "Right Curve" 27 "Left Curve" 28 "Winding Road" 29 "Reserved" 30 "Reserved" 31 "Reserved";
VAL_ 676 LEFT_LANE_LINE 0 "Not Detected" 1 "Low Confidence" 2 "Medium Confidence" 3 "High Confidence";
VAL_ 676 RIGHT_LANE_LINE 0 "Not Detected" 1 "Low Confidence" 2 "Medium Confidence" 3 "High Confidence";
VAL_ 687 HOD_Dir_Status 0 "HANDS OFF" 1 "HAND TOUCH (SOFT)" 2 "HAND TOUCH (STRONG)" 3 "HAND GRIP (SOFT)" 4 "HAND GRIP (STRONG)" 5 "RESERVED" 6 "RESERVED";
VAL_ 698 Status 0 "None Option" 1 "Normal" 2 "Blockage Status" 3 "Error Indicator";
VAL_ 698 VehNumVal 0 "No vehicle" 1 "Number of vehicles" 2 "Number of vehicles" 3 "Number of vehicles" 4 "Number of vehicles" 5 "Number of vehicles" 6 "Number of vehicles" 7 "Number of vehicles" 8 "Number of vehicles" 9 "Number of vehicles" 10 "Number of vehicles" 11 "Over than 10 vehicles" 12 "Reserved" 13 "Reserved" 14 "Default" 15 "Error indicator";
VAL_ 698 ILLAmbtSta 0 "Bright" 1 "Dark" 2 "Not used" 3 "Error indicator";
VAL_ 698 VehLeftAngl1Val 501 "Not used" 502 "Not used" 503 "Not used" 504 "Not used" 505 "Not used" 506 "Not used" 507 "Not used" 508 "Not used" 509 "Not used" 510 "Default" 511 "Error indicator";
VAL_ 698 VehRightAngl1Val 501 "Not used" 502 "Not used" 503 "Not used" 504 "Not used" 505 "Not used" 506 "Not used" 507 "Not used" 508 "Not used" 509 "Not used" 510 "Default" 511 "Error indicator";
VAL_ 698 VehLeftAngl2Val 501 "Not used" 502 "Not used" 503 "Not used" 504 "Not used" 505 "Not used" 506 "Not used" 507 "Not used" 508 "Not used" 509 "Not used" 510 "Default" 511 "Error indicator";
VAL_ 698 VehDst1Val 0 "No Value" 1 "1~10m" 2 "11~20m" 3 "21~30m" 4 "31~40m" 5 "41~50m" 6 "51~60m" 7 "61~70m" 8 "71~80m" 9 "81~90m" 10 "91~100m" 11 "101~200m" 12 "201~300m" 13 "301~400m" 14 "401m~" 15 "Error indicator";
VAL_ 698 VehRightAngl2Val 501 "Not used" 502 "Not used" 503 "Not used" 504 "Not used" 505 "Not used" 506 "Not used" 507 "Not used" 508 "Not used" 509 "Not used" 510 "Default" 511 "Error indicator";
VAL_ 698 VehLeftAngl3Val 501 "Not used" 502 "Not used" 503 "Not used" 504 "Not used" 505 "Not used" 506 "Not used" 507 "Not used" 508 "Not used" 509 "Not used" 510 "Default" 511 "Error indicator";
VAL_ 698 VehRightAngl3Val 501 "Not used" 502 "Not used" 503 "Not used" 504 "Not used" 505 "Not used" 506 "Not used" 507 "Not used" 508 "Not used" 509 "Not used" 510 "Default" 511 "Error indicator";
VAL_ 698 VehLeftAngl4Val 501 "Not used" 502 "Not used" 503 "Not used" 504 "Not used" 505 "Not used" 506 "Not used" 507 "Not used" 508 "Not used" 509 "Not used" 510 "Default" 511 "Error indicator";
VAL_ 698 VehRightAngl4Val 501 "Not used" 502 "Not used" 503 "Not used" 504 "Not used" 505 "Not used" 506 "Not used" 507 "Not used" 508 "Not used" 509 "Not used" 510 "Default" 511 "Error indicator";
VAL_ 698 VehLeftAngl5Val 501 "Not used" 502 "Not used" 503 "Not used" 504 "Not used" 505 "Not used" 506 "Not used" 507 "Not used" 508 "Not used" 509 "Not used" 510 "Default" 511 "Error indicator";
VAL_ 698 VehRightAngl5Val 501 "Not used" 502 "Not used" 503 "Not used" 504 "Not used" 505 "Not used" 506 "Not used" 507 "Not used" 508 "Not used" 509 "Not used" 510 "Default" 511 "Error indicator";
VAL_ 698 VehLeftAngl6Val 501 "Not used" 502 "Not used" 503 "Not used" 504 "Not used" 505 "Not used" 506 "Not used" 507 "Not used" 508 "Not used" 509 "Not used" 510 "Default" 511 "Error indicator";
VAL_ 698 VehRightAngl6Val 501 "Not used" 502 "Not used" 503 "Not used" 504 "Not used" 505 "Not used" 506 "Not used" 507 "Not used" 508 "Not used" 509 "Not used" 510 "Default" 511 "Error indicator";
VAL_ 698 VehLeftAngl7Val 501 "Not used" 502 "Not used" 503 "Not used" 504 "Not used" 505 "Not used" 506 "Not used" 507 "Not used" 508 "Not used" 509 "Not used" 510 "Default" 511 "Error indicator";
VAL_ 698 VehRightAngl7Val 501 "Not used" 502 "Not used" 503 "Not used" 504 "Not used" 505 "Not used" 506 "Not used" 507 "Not used" 508 "Not used" 509 "Not used" 510 "Default" 511 "Error indicator";
VAL_ 698 VehLeftAngl8Val 501 "Not used" 502 "Not used" 503 "Not used" 504 "Not used" 505 "Not used" 506 "Not used" 507 "Not used" 508 "Not used" 509 "Not used" 510 "Default" 511 "Error indicator";
VAL_ 698 VehRightAngl8Val 501 "Not used" 502 "Not used" 503 "Not used" 504 "Not used" 505 "Not used" 506 "Not used" 507 "Not used" 508 "Not used" 509 "Not used" 510 "Default" 511 "Error indicator";
VAL_ 698 VehLeftAngl9Val 501 "Not used" 502 "Not used" 503 "Not used" 504 "Not used" 505 "Not used" 506 "Not used" 507 "Not used" 508 "Not used" 509 "Not used" 510 "Default" 511 "Error indicator";
VAL_ 698 VehRightAngl9Val 501 "Not used" 502 "Not used" 503 "Not used" 504 "Not used" 505 "Not used" 506 "Not used" 507 "Not used" 508 "Not used" 509 "Not used" 510 "Default" 511 "Error indicator";
VAL_ 698 VehLeftAngl10Val 501 "Not used" 502 "Not used" 503 "Not used" 504 "Not used" 505 "Not used" 506 "Not used" 507 "Not used" 508 "Not used" 509 "Not used" 510 "Default" 511 "Error indicator";
VAL_ 698 VehRightAngl10Val 501 "Not used" 502 "Not used" 503 "Not used" 504 "Not used" 505 "Not used" 506 "Not used" 507 "Not used" 508 "Not used" 509 "Not used" 510 "Default" 511 "Error indicator";
VAL_ 698 VehDst2Val 0 "No Value" 1 "1~10m" 2 "11~20m" 3 "21~30m" 4 "31~40m" 5 "41~50m" 6 "51~60m" 7 "61~70m" 8 "71~80m" 9 "81~90m" 10 "91~100m" 11 "101~200m" 12 "201~300m" 13 "301~400m" 14 "401m~" 15 "Error indicator";
VAL_ 698 VehDst3Val 0 "No Value" 1 "1~10m" 2 "11~20m" 3 "21~30m" 4 "31~40m" 5 "41~50m" 6 "51~60m" 7 "61~70m" 8 "71~80m" 9 "81~90m" 10 "91~100m" 11 "101~200m" 12 "201~300m" 13 "301~400m" 14 "401m~" 15 "Error indicator";
VAL_ 698 VehDst4Val 0 "No Value" 1 "1~10m" 2 "11~20m" 3 "21~30m" 4 "31~40m" 5 "41~50m" 6 "51~60m" 7 "61~70m" 8 "71~80m" 9 "81~90m" 10 "91~100m" 11 "101~200m" 12 "201~300m" 13 "301~400m" 14 "401m~" 15 "Error indicator";
VAL_ 698 VehDst5Val 0 "No Value" 1 "1~10m" 2 "11~20m" 3 "21~30m" 4 "31~40m" 5 "41~50m" 6 "51~60m" 7 "61~70m" 8 "71~80m" 9 "81~90m" 10 "91~100m" 11 "101~200m" 12 "201~300m" 13 "301~400m" 14 "401m~" 15 "Error indicator";
VAL_ 698 VehDst6Val 0 "No Value" 1 "1~10m" 2 "11~20m" 3 "21~30m" 4 "31~40m" 5 "41~50m" 6 "51~60m" 7 "61~70m" 8 "71~80m" 9 "81~90m" 10 "91~100m" 11 "101~200m" 12 "201~300m" 13 "301~400m" 14 "401m~" 15 "Error indicator";
VAL_ 698 VehDst7Val 0 "No Value" 1 "1~10m" 2 "11~20m" 3 "21~30m" 4 "31~40m" 5 "41~50m" 6 "51~60m" 7 "61~70m" 8 "71~80m" 9 "81~90m" 10 "91~100m" 11 "101~200m" 12 "201~300m" 13 "301~400m" 14 "401m~" 15 "Error indicator";
VAL_ 698 VehDst8Val 0 "No Value" 1 "1~10m" 2 "11~20m" 3 "21~30m" 4 "31~40m" 5 "41~50m" 6 "51~60m" 7 "61~70m" 8 "71~80m" 9 "81~90m" 10 "91~100m" 11 "101~200m" 12 "201~300m" 13 "301~400m" 14 "401m~" 15 "Error indicator";
VAL_ 698 VehDst9Val 0 "No Value" 1 "1~10m" 2 "11~20m" 3 "21~30m" 4 "31~40m" 5 "41~50m" 6 "51~60m" 7 "61~70m" 8 "71~80m" 9 "81~90m" 10 "91~100m" 11 "101~200m" 12 "201~300m" 13 "301~400m" 14 "401m~" 15 "Error indicator";
VAL_ 698 VehDst10Val 0 "No Value" 1 "1~10m" 2 "11~20m" 3 "21~30m" 4 "31~40m" 5 "41~50m" 6 "51~60m" 7 "61~70m" 8 "71~80m" 9 "81~90m" 10 "91~100m" 11 "101~200m" 12 "201~300m" 13 "301~400m" 14 "401m~" 15 "Error indicator";
VAL_ 736 MSLA_STATUS 0 "disabled" 1 "active" 2 "paused";
VAL_ 866 LEFT_LANE_LINE 0 "Not Detected" 1 "Low Confidence" 2 "Medium Confidence" 3 "High Confidence";
VAL_ 866 RIGHT_LANE_LINE 0 "Not Detected" 1 "Low Confidence" 2 "Medium Confidence" 3 "High Confidence";
VAL_ 1041 FL_DOOR 0 "Closed" 1 "Opened";
VAL_ 1041 FR_DOOR 0 "Closed" 1 "Opened";
VAL_ 1041 FR_SEATBELT 0 "Unlatched" 1 "Latched";
VAL_ 1041 FL_SEATBELT 0 "Unlatched" 1 "Latched";
VAL_ 1041 RL_DOOR 0 "Closed" 1 "Opened";
VAL_ 1041 RR_DOOR 0 "Closed" 1 "Opened";
VAL_ 1079 TRAILER_CONNECTED 1 "CONNECTED" 0 "DISCONNECTED";
VAL_ 1144 DRIVE_MODE2 3 "Set Sport" 1 "Set Normal" 2 "Set Eco";
VAL_ 1240 DISTANCE_UNIT 1 "Miles" 0 "Kilometers";
